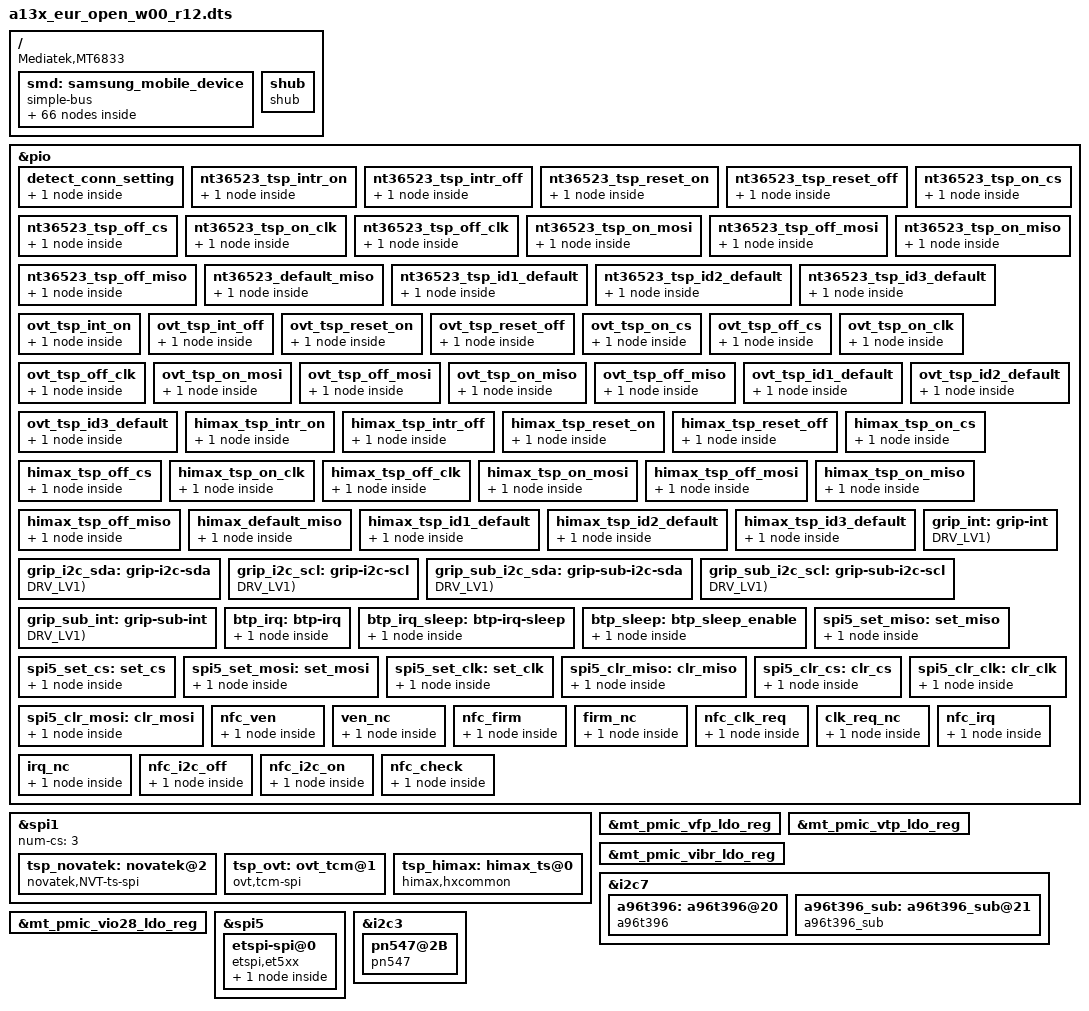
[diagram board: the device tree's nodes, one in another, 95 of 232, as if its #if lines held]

/*
 * Copyright (c) 2018 Samsung Electronics Co., Ltd.
 *              http://www.samsung.com
 *
 * This program is free software; you can redistribute it and/or modify
 * it under the terms of the GNU General Public License version 2 as
 * published by the Free Software Foundation.
*/

/dts-v1/;
/plugin/;
/ {
	fragment@smd {
		target-path = "/";
		__overlay__ {
			smd: samsung_mobile_device {
				compatible = "simple-bus";
			};
		};
	};
};

/* #include "../mtk_charger.dtsi" */                 /* From mtk_charger.py */

&smd {
	mtk_charger: mtk-charger {
		compatible = "samsung,mtk-charger";
		charger,vbus_min_charger_voltage = <4500000>;
		charger,vbus_normal_mivr_voltage = <4500000>;
		charger,gpio_ilim = <&pio 140 0x0>;
		charger,gpio_chgenb = <&pio 135 0x0>;
		charger,max_icl = <3250>;
		charger,ib_fcc = <100>;
	};
};

/* #include "../mtk_fuelgauge.dtsi" */               /* From mtk_fuelgauge.py */
&smd {
	battery {
		battery,fuelgauge_name = "mtk-fg-battery";
	};

	/* battery_prop.dtsi */
	bat_gm30: mtk_battery{
		compatible = "mediatek,bat_gm30";
		DIFFERENCE_FULLOCV_ITH = <(300)>;
	/*	Charging termination current*/
		SHUTDOWN_1_TIME = <(60)>;
	/*	If ui_soc shows 1% more than X minites, system will shutdown*/
		KEEP_100_PERCENT = <(1)>;
	/* 	The ui_soc will keep 100% until SOC drop X percents after unplugged */
		R_FG_VALUE = <(5)>;
	/*	R_sense resistance*/
		EMBEDDED_SEL = <(0)>;
	/*	Configures whether using embedded battery or not*/
		PMIC_SHUTDOWN_CURRENT = <(20)>;
	/*	System shutdown current*/
		FG_METER_RESISTANCE = <(100)>;
	/*	The resistance of PCB*/
		CAR_TUNE_VALUE = <(99)>;
	/*	Tune value for current measurement*/
		PMIC_MIN_VOL = <(33500)>;
	/*	vboot voltage for gauge 0%*/
		POWERON_SYSTEM_IBOOT = <(500)>;
	/*	power on system iboot*/
		SHUTDOWN_GAUGE0 = <(0)>;
	/*	Shutdown condition2 switch*/
		SHUTDOWN_GAUGE0_VOLTAGE = <(34000)>;
	/*	shutdown gauge 0% voltage*/
		TEMPERATURE_T0 = <(50)>;
	/*	Battery temperature T0*/
		TEMPERATURE_T1 = <(25)>;
	/*	Battery temperature T1*/
		TEMPERATURE_T2 = <(10)>;
	/*	Battery temperature T2*/
		TEMPERATURE_T3 = <(0)>;
	/*	Battery temperature T3*/
		TEMPERATURE_T4 = <(-10)>;
	/*	Battery temperature T4*/
		TEMPERATURE_T5 = <(-20)>;
	/*	Battery temperature T5*/
		g_FG_PSEUDO100_T0 = <(93)>;
	/*	Pseudo 100% percentage at T0*/
		g_FG_PSEUDO100_T1 = <(93)>;
	/*	Pseudo 100% percentage at T1*/
		g_FG_PSEUDO100_T2 = <(93)>;
	/*	Pseudo 100% percentage at T2*/
		g_FG_PSEUDO100_T3 = <(93)>;
	/*	Pseudo 100% percentage at T3*/
		g_FG_PSEUDO100_T4 = <(93)>;
	/*	Pseudo 100% percentage at T4*/
		g_FG_PSEUDO100_T5 = <(93)>;
	/*	Pseudo 100% percentage at T4*/
		Q_MAX_SYS_VOLTAGE_BAT0 = <(3350)>;
	/*	Pseudo1 for hide percentage*/
		Q_MAX_SYS_VOLTAGE_BAT1 = <(3350)>;
	/*	Pseudo1 for hide percentage*/
		Q_MAX_SYS_VOLTAGE_BAT2 = <(3350)>;
	/*	Pseudo1 for hide percentage*/
		Q_MAX_SYS_VOLTAGE_BAT3 = <(3350)>;
	/*	Pseudo1 for hide percentage*/
		COM_FG_METER_RESISTANCE = <(100)>;
	/*	compensate The resistance of PCB*/
		COM_R_FG_VALUE = <(0)>;
	/*	compensate R_sense resistance*/
		enable_tmp_intr_suspend = <(0)>;
	/* Enable update temp when suspend */
		ACTIVE_TABLE = <(6)>;
	/* Table numbers per battery*/
		MULTI_TEMP_GAUGE0 = <(1)>;
	/* Multi gauge0 enable*/
		HWOCV_OLDOCV_DIFF = <(100)>;
	/* Diff of HWOCV and SWOCV*/
	UI_FULL_LIMIT_EN = <(1)>;
	UI_FULL_LIMIT_SOC0 = <(9500)>;
	UI_FULL_LIMIT_ITH0 = <(8500)>;
	UI_FULL_LIMIT_SOC1 = <(9600)>;
	UI_FULL_LIMIT_ITH1 = <(7500)>;
	UI_FULL_LIMIT_SOC2 = <(9700)>;
	UI_FULL_LIMIT_ITH2 = <(6600)>;
	UI_FULL_LIMIT_SOC3 = <(9800)>;
	UI_FULL_LIMIT_ITH3 = <(6000)>;
	UI_FULL_LIMIT_SOC4 = <(9900)>;
	UI_FULL_LIMIT_ITH4 = <(5000)>;
/* Using current to limit uisoc in 100% case*/
	/* battery_table.dtsi*/
	battery0_profile_t0_num = <100>;
	battery0_profile_t0_col = <3>;
	battery0_profile_t0 =
	<
	0       43520   850
	486     43380   866
	972     43251   875
	1458    43130   897
	1944    43004   875
	2430    42881   875
	2916    42760   875
	3402    42644   875
	3888    42530   900
	4375    42407   875
	4861    42293   881
	5347    42178   900
	5833    42054   875
	6319    41941   897
	6805    41820   875
	7291    41714   875
	7777    41601   900
	8263    41485   875
	8749    41372   875
	9235    41267   897
	9721    41155   875
	10207   41051   875
	10693   40945   875
	11179   40837   884
	11665   40739   875
	12152   40642   900
	12638   40542   894
	13124   40446   919
	13610   40350   900
	14096   40253   900
	14582   40162   919
	15068   40070   925
	15554   39979   925
	16040   39898   941
	16526   39817   950
	17012   39736   950
	17498   39655   962
	17984   39573   975
	18470   39492   975
	18956   39411   1000
	19442   39329   1025
	19928   39210   975
	20415   39078   938
	20901   38949   878
	21387   38849   875
	21873   38773   850
	22359   38699   850
	22845   38635   850
	23331   38580   850
	23817   38521   850
	24303   38472   850
	24789   38423   850
	25275   38374   875
	25761   38326   850
	26247   38285   869
	26733   38239   850
	27219   38200   875
	27705   38157   866
	28192   38115   868
	28678   38082   872
	29164   38050   875
	29650   38007   853
	30136   37975   875
	30622   37952   900
	31108   37919   900
	31594   37887   900
	32080   37865   907
	32566   37841   925
	33052   37810   925
	33538   37765   900
	34024   37684   861
	34510   37614   865
	34996   37550   851
	35482   37511   859
	35968   37465   857
	36455   37424   853
	36941   37374   850
	37427   37337   875
	37913   37304   875
	38399   37272   875
	38885   37230   875
	39371   37185   900
	39857   37120   875
	40343   37063   875
	40829   37004   888
	41315   36942   879
	41801   36861   881
	42287   36806   860
	42773   36790   875
	43259   36780   891
	43745   36767   907
	44232   36751   948
	44718   36719   976
	45204   36643   1018
	45690   36372   937
	46176   35944   969
	46662   35387   1000
	47148   34581   1041
	47634   33318   1181
	48120   30130   10325
	>;
	battery0_profile_t1_num = <100>;
	battery0_profile_t1_col = <3>;
	battery0_profile_t1 =
	<
	0       43320   1450
	486     43164   1450
	972     43033   1475
	1458    42911   1475
	1944    42789   1475
	2430    42671   1475
	2916    42550   1456
	3402    42434   1475
	3888    42320   1475
	4375    42197   1440
	4861    42083   1431
	5347    41968   1428
	5833    41854   1437
	6319    41741   1428
	6805    41628   1431
	7291    41514   1425
	7777    41401   1425
	8263    41295   1425
	8749    41184   1407
	9235    41078   1403
	9721    40975   1412
	10207   40871   1425
	10693   40765   1425
	11179   40667   1416
	11665   40569   1425
	12152   40475   1450
	12638   40382   1450
	13124   40277   1450
	13610   40190   1450
	14096   40093   1447
	14582   40002   1444
	15068   39920   1460
	15554   39839   1450
	16040   39758   1450
	16526   39687   1500
	17012   39606   1500
	17498   39525   1500
	17984   39443   1504
	18470   39354   1525
	18956   39243   1490
	19442   39109   1425
	19928   38980   1344
	20415   38875   1319
	20901   38787   1300
	21387   38719   1313
	21873   38654   1300
	22359   38589   1300
	22845   38535   1290
	23331   38480   1300
	23817   38431   1291
	24303   38384   1300
	24789   38343   1300
	25275   38294   1300
	25761   38257   1303
	26247   38217   1325
	26733   38182   1309
	27219   38140   1325
	27705   38107   1341
	28192   38075   1332
	28678   38042   1350
	29164   38010   1350
	29650   37987   1375
	30136   37955   1375
	30622   37926   1375
	31108   37900   1376
	31594   37877   1384
	32080   37855   1400
	32566   37822   1378
	33052   37790   1375
	33538   37747   1375
	34024   37707   1356
	34510   37672   1360
	34996   37630   1351
	35482   37591   1359
	35968   37552   1350
	36455   37512   1372
	36941   37480   1375
	37427   37447   1375
	37913   37414   1394
	38399   37368   1385
	38885   37310   1376
	39371   37248   1393
	39857   37192   1400
	40343   37134   1423
	40829   37063   1412
	41315   36975   1425
	41801   36935   1425
	42287   36920   1460
	42773   36910   1475
	43259   36894   1500
	43745   36867   1514
	44232   36833   1573
	44718   36727   1613
	45204   36421   1607
	45690   35937   1688
	46176   35299   1804
	46662   34415   1951
	47148   32710   2488
	47634   30570   11550
	48120   30570   11550
	>;
	battery0_profile_t2_num = <100>;
	battery0_profile_t2_col = <3>;
	battery0_profile_t2 =
	<
	0       43000   3200
	486     42808   3293
	972     42661   3412
	1458    42531   3472
	1944    42404   3476
	2430    42281   3478
	2916    42160   3481
	3402    42044   3484
	3888    41930   3475
	4375    41817   3485
	4861    41695   3456
	5347    41579   3431
	5833    41474   3450
	6319    41361   3425
	6805    41255   3425
	7291    41144   3425
	7777    41041   3425
	8263    40931   3416
	8749    40834   3407
	9235    40737   3425
	9721    40640   3425
	10207   40541   3444
	10693   40435   3419
	11179   40337   3425
	11665   40229   3375
	12152   40138   3391
	12638   40047   3381
	13124   39957   3378
	13610   39875   3400
	14096   39794   3375
	14582   39712   3375
	15068   39640   3415
	15554   39559   3425
	16040   39472   3409
	16526   39382   3425
	17012   39269   3381
	17498   39146   3350
	17984   39008   3268
	18470   38894   3225
	18956   38801   3200
	19442   38720   3200
	19928   38655   3200
	20415   38590   3200
	20901   38534   3222
	21387   38479   3225
	21873   38426   3250
	22359   38377   3250
	22845   38329   3275
	23331   38280   3275
	23817   38241   3300
	24303   38202   3325
	24789   38162   3347
	25275   38130   3363
	25761   38087   3378
	26247   38055   3400
	26733   38022   3425
	27219   37990   3425
	27705   37967   3466
	28192   37935   3500
	28678   37911   3500
	29164   37885   3525
	29650   37859   3528
	30136   37842   3569
	30622   37822   3600
	31108   37800   3601
	31594   37784   3641
	32080   37757   3657
	32566   37732   3697
	33052   37700   3700
	33538   37667   3728
	34024   37627   3750
	34510   37592   3795
	34996   37559   3850
	35482   37517   3866
	35968   37482   3932
	36455   37434   3972
	36941   37374   4026
	37427   37314   4104
	37913   37249   4144
	38399   37190   4235
	38885   37119   4325
	39371   37028   4398
	39857   36965   4501
	40343   36932   4666
	40829   36905   4816
	41315   36877   5048
	41801   36845   5310
	42287   36790   5653
	42773   36689   6028
	43259   36466   6433
	43745   36033   6914
	44232   35419   7720
	44718   34544   8974
	45204   33115   11297
	45690   30950   12525
	46176   30950   12525
	46662   30950   12525
	47148   30950   12525
	47634   30950   12525
	48120   30950   12525
	>;
	battery0_profile_t3_num = <100>;
	battery0_profile_t3_col = <3>;
	battery0_profile_t3 =
	<
	0       42520   5950
	486     42262   6183
	972     42098   6518
	1458    41961   6640
	1944    41824   6714
	2430    41701   6753
	2916    41580   6775
	3402    41464   6816
	3888    41350   6825
	4375    41237   6840
	4861    41123   6825
	5347    41017   6847
	5833    40909   6825
	6319    40812   6847
	6805    40715   6844
	7291    40604   6825
	7777    40501   6825
	8263    40385   6784
	8749    40274   6782
	9235    40177   6800
	9721    40080   6800
	10207   39984   6778
	10693   39903   6781
	11179   39821   6784
	11665   39739   6800
	12152   39658   6791
	12638   39587   6825
	13124   39497   6803
	13610   39410   6813
	14096   39312   6797
	14582   39196   6756
	15068   39069   6680
	15554   38949   6625
	16040   38836   6584
	16526   38747   6569
	17012   38666   6550
	17498   38600   6575
	17984   38536   6579
	18470   38479   6600
	18956   38418   6635
	19442   38370   6675
	19928   38321   6691
	20415   38275   6706
	20901   38234   6725
	21387   38194   6750
	21873   38156   6775
	22359   38115   6794
	22845   38082   6835
	23331   38050   6850
	23817   38018   6891
	24303   37984   6907
	24789   37952   6925
	25275   37930   6975
	25761   37909   7003
	26247   37892   7044
	26733   37876   7084
	27219   37860   7125
	27705   37843   7183
	28192   37827   7214
	28678   37811   7295
	29164   37795   7351
	29650   37777   7407
	30136   37752   7488
	30622   37722   7544
	31108   37689   7626
	31594   37657   7723
	32080   37622   7813
	32566   37582   7939
	33052   37540   8076
	33538   37495   8238
	34024   37437   8422
	34510   37374   8610
	34996   37309   8853
	35482   37238   9080
	35968   37170   9352
	36455   37096   9676
	36941   37004   10017
	37427   36935   10393
	37913   36894   10858
	38399   36862   11389
	38885   36830   11982
	39371   36791   12670
	39857   36740   13453
	40343   36656   14301
	40829   36424   15025
	41315   35986   15823
	41801   35349   16953
	42287   34442   18475
	42773   33430   18575
	43259   33430   18575
	43745   33430   18575
	44232   33430   18575
	44718   33430   18575
	45204   33430   18575
	45690   33430   18575
	46176   33430   18575
	46662   33430   18575
	47148   33430   18575
	47634   33430   18575
	48120   33430   18575
	>;
	battery0_profile_t4_num = <100>;
	battery0_profile_t4_col = <3>;
	battery0_profile_t4 =
	<
	0       42010   11330
	486     41738   11604
	972     41429   12066
	1458    41171   12469
	1944    40989   12751
	2430    40838   12878
	2916    40700   12919
	3402    40570   12916
	3888    40440   12875
	4375    40311   12819
	4861    40181   12744
	5347    40058   12703
	5833    39949   12675
	6319    39842   12650
	6805    39745   12650
	7291    39648   12616
	7777    39541   12526
	8263    39441   12509
	8749    39332   12437
	9235    39227   12378
	9721    39115   12312
	10207   39013   12272
	10693   38923   12250
	11179   38841   12216
	11665   38759   12200
	12152   38694   12184
	12638   38622   12175
	13124   38565   12175
	13610   38510   12200
	14096   38456   12178
	14582   38407   12200
	15068   38358   12210
	15554   38310   12225
	16040   38261   12241
	16526   38215   12256
	17012   38174   12297
	17498   38140   12325
	17984   38097   12329
	18470   38065   12350
	18956   38032   12375
	19442   38010   12450
	19928   37977   12475
	20415   37955   12506
	20901   37931   12568
	21387   37905   12626
	21873   37874   12675
	22359   37855   12770
	22845   37832   12819
	23331   37800   12900
	23817   37778   13031
	24303   37744   13121
	24789   37712   13242
	25275   37670   13327
	25761   37626   13460
	26247   37577   13639
	26733   37535   13728
	27219   37480   13875
	27705   37420   14031
	28192   37359   14202
	28678   37294   14386
	29164   37230   14552
	29650   37155   14720
	30136   37090   14944
	30622   37028   15148
	31108   36979   15354
	31594   36947   15613
	32080   36905   15847
	32566   36863   16130
	33052   36790   16376
	33538   36673   16644
	34024   36429   16891
	34510   36018   17215
	34996   35399   17761
	35482   34431   18699
	35968   32802   17069
	36455   31080   12750
	36941   31080   12750
	37427   31080   12750
	37913   31080   12750
	38399   31080   12750
	38885   31080   12750
	39371   31080   12750
	39857   31080   12750
	40343   31080   12750
	40829   31080   12750
	41315   31080   12750
	41801   31080   12750
	42287   31080   12750
	42773   31080   12750
	43259   31080   12750
	43745   31080   12750
	44232   31080   12750
	44718   31080   12750
	45204   31080   12750
	45690   31080   12750
	46176   31080   12750
	46662   31080   12750
	47148   31080   12750
	47634   31080   12750
	48120   31080   12750
	>;
	battery0_profile_t5_num = <100>;
	battery0_profile_t5_col = <3>;
	battery0_profile_t5 =
	<
	0       40920   10780
	483     40610   11233
	967     40337   12231
	1450    40095   12975
	1933    39872   13686
	2417    39674   14479
	2900    39510   15208
	3383    39378   15667
	3867    39258   15931
	4350    39150   16075
	4833    39042   16178
	5317    38929   16164
	5800    38830   16208
	6283    38733   16319
	6767    38652   16378
	7250    38573   16404
	7733    38509   16464
	8217    38444   16519
	8700    38390   16625
	9183    38335   16666
	9667    38292   16706
	10150   38244   16725
	10633   38200   16750
	11117   38158   16752
	11600   38126   16810
	12083   38087   16833
	12567   38052   16965
	13050   38019   16990
	13533   37987   17100
	14017   37955   17176
	14500   37919   17218
	14983   37880   17323
	15467   37838   17390
	15950   37794   17510
	16433   37738   17550
	16917   37683   17714
	17400   37629   17828
	17883   37564   17981
	18367   37500   18070
	18850   37427   18222
	19333   37361   18385
	19817   37286   18407
	20300   37222   18563
	20783   37158   18764
	21267   37093   18919
	21750   37039   19080
	22233   36974   19247
	22717   36910   19451
	23200   36824   19655
	23683   36692   19921
	24167   36470   20134
	24650   36118   20420
	25133   35546   20803
	25617   34662   21167
	26100   33270   18200
	26583   32530   16450
	27067   32530   16450
	27550   32530   16450
	28033   32530   16450
	28517   32530   16450
	29000   32530   16450
	29483   32530   16450
	29967   32530   16450
	30450   32530   16450
	30933   32530   16450
	31417   32530   16450
	31900   32530   16450
	32383   32530   16450
	32867   32530   16450
	33350   32530   16450
	33833   32530   16450
	34317   32530   16450
	34800   32530   16450
	35283   32530   16450
	35767   32530   16450
	36250   32530   16450
	36733   32530   16450
	37217   32530   16450
	37700   32530   16450
	38183   32530   16450
	38667   32530   16450
	39150   32530   16450
	39633   32530   16450
	40117   32530   16450
	40600   32530   16450
	41083   32530   16450
	41567   32530   16450
	42050   32530   16450
	42533   32530   16450
	43017   32530   16450
	43500   32530   16450
	43983   32530   16450
	44467   32530   16450
	44950   32530   16450
	45433   32530   16450
	45917   32530   16450
	46400   32530   16450
	46883   32530   16450
	47367   32530   16450
	47850   32530   16450
	>;

	/* battery_prop_dim2_ext.dtsi */
	/*vboot voltage for gauge 0%*/
	g_PMIC_MIN_VOL_row = <4>;
	g_PMIC_MIN_VOL_col = <10>;
	g_PMIC_MIN_VOL =
	<
		32700  32700  32700  32700
		32700  32700  32700  32700
		32700  32700  32700  32700
		32200  32200  32200  32200
		31000  31000  31000  31000
		31500  31500  31500  31500
		31000  31000  31000  31000
		31000  31000  31000  31000
		31000  31000  31000  31000
		31000  31000  31000  31200
	>;
	/*boot_up current for gauge 0%*/
	g_PON_SYS_IBOOT_row = <4>;
	g_PON_SYS_IBOOT_col = <10>;
	g_PON_SYS_IBOOT =
	<
		5000  5000  5000  5000
		5000  5000  5000  5000
		5000  5000  5000  5000
		5000  5000  5000  5000
		5000  5000  5000  5000
		5000  5000  5000  5000
		5000  5000  5000  5000
		5000  5000  5000  5000
		5000  5000  5000  5000
		5000  5000  5000  5000
	>;
	/*Pseudo1 hide percentage*/
	g_QMAX_SYS_VOL_row = <4>;
	g_QMAX_SYS_VOL_col = <10>;
	g_QMAX_SYS_VOL =
	<
		33600  33600  33600  33600
		33600  33600  33600  33600
		33600  33600  33600  33600
		33600  33600  33600  33600
		33600  33600  33600  33600
		32500  32500  32500  32500
		32800  32800  32800  32800
		32800  32800  32800  32800
		32800  32800  32800  32800
		32800  32800  32800  32800
	>;
	/*Pseudo100 percentage setting*/
	g_FG_PSEUDO100_row = <4>;
	g_FG_PSEUDO100_col = <10>;
	g_FG_PSEUDO100 =
	<
		91  100  100  100
		91  100  100  100
		91  100  100  100
		91  100  100  100
		91  100  100  100
		91  100  100  100
		100  100  100  100
		100  100  100  100
		100  100  100  100
		100  100  100  100
	>;

	};
};

/* /home/dpi/qb5_8814/workspace/P4_1716/android/kernel/kmodule/battery/fuelgauge/mtk_fuelgauge/mtk_fuelgauge.a13x.dtsi */
&smd {
	battery {
		battery,fuelgauge_name = "mtk-fg-battery";
	};

	/* battery_prop.dtsi */
bat_gm30: mtk_battery{
	compatible = "mediatek,bat_gm30";

	RBAT_TYPE = <(100)>;
	RBAT_PULL_UP_R = <(100000)>;

	rbat_temperature_table_num = <21>;
	rbat_battery_temperature =
	<
		(-40) 4397119
		(-35) 3088598
		(-30) 2197225
		(-25) 1581880
		(-20) 1151036
		(-15) 846578
		(-10) 628988
		(-5) 471632
		0 357011
		5 272499
		10 209709
		15 162650
		20 127080
		25 100000
		30 79221
		35 63167
		40 50676
		45 40903
		50 33194
		55 27090
		60 22224 >;
/* battery temperature table type - NTC table */
	BatteryID_GPIO = <&pio 184 0>;
/* Battery ID distinction */
	DIFFERENCE_FULLOCV_ITH = <(300)>; /* a13x-5g : 300mA */
/*	Charging termination current*/
	SHUTDOWN_1_TIME = <(60)>;
/*	If ui_soc shows 1% more than X minites, system will shutdown*/
	KEEP_100_PERCENT = <(1)>;
/*	The ui_soc will keep 100% until SOC drop X percents after unplugged*/
	R_FG_VALUE = <(5)>;
/*	R_sense resistance*/
	EMBEDDED_SEL = <(0)>;
/*	Configures whether using embedded battery or not*/
	PMIC_SHUTDOWN_CURRENT = <(20)>;
/*	System shutdown current*/
	FG_METER_RESISTANCE = <(100)>;
/*	The resistance of PCB*/
	CAR_TUNE_VALUE = <(102)>;
/*	Tune value for current measurement*/
	PMIC_MIN_VOL = <(33500)>;
/*	vboot voltage for gauge 0%*/
	POWERON_SYSTEM_IBOOT = <(500)>;
/*	power on system iboot*/
	SHUTDOWN_GAUGE0 = <(0)>;
/*	Shutdown condition2 switch*/
	SHUTDOWN_GAUGE0_VOLTAGE = <(34000)>;
/*	shutdown gauge 0% voltage*/
	TEMPERATURE_T0 = <(50)>;
/*	Battery temperature T0*/
	TEMPERATURE_T1 = <(25)>;
/*	Battery temperature T1*/
	TEMPERATURE_T2 = <(10)>;
/*	Battery temperature T2*/
	TEMPERATURE_T3 = <(0)>;
/*	Battery temperature T3*/
	TEMPERATURE_T4 = <(-10)>;
/*	Battery temperature T4*/
	TEMPERATURE_T5 = <(-20)>;
/*	Battery temperature T5*/
	g_FG_PSEUDO100_T0 = <(100)>;
/*	Pseudo 100% percentage at T0*/
	g_FG_PSEUDO100_T1 = <(100)>;
/*	Pseudo 100% percentage at T1*/
	g_FG_PSEUDO100_T2 = <(100)>;
/*	Pseudo 100% percentage at T2*/
	g_FG_PSEUDO100_T3 = <(100)>;
/*	Pseudo 100% percentage at T3*/
	g_FG_PSEUDO100_T4 = <(100)>;
/*	Pseudo 100% percentage at T4*/
	g_FG_PSEUDO100_T5 = <(100)>;
/*	Pseudo 100% percentage at T4*/
	Q_MAX_SYS_VOLTAGE_BAT0 = <(3350)>;
/*	Pseudo1 for hide percentage*/
	Q_MAX_SYS_VOLTAGE_BAT1 = <(3350)>;
/*	Pseudo1 for hide percentage*/
	Q_MAX_SYS_VOLTAGE_BAT2 = <(3350)>;
/*	Pseudo1 for hide percentage*/
	Q_MAX_SYS_VOLTAGE_BAT3 = <(3350)>;
/*	Pseudo1 for hide percentage*/
	COM_FG_METER_RESISTANCE = <(100)>;
/*	compensate The resistance of PCB*/
	COM_R_FG_VALUE = <(0)>;
/*	compensate R_sense resistance*/
	enable_tmp_intr_suspend = <(0)>;
/* Enable update temp when suspend */
	ACTIVE_TABLE = <(6)>;
/* Table numbers per battery*/
	MULTI_TEMP_GAUGE0 = <(1)>;
/* Multi gauge0 enable*/
	HWOCV_OLDOCV_DIFF = <(100)>;
/* Diff of HWOCV and SWOCV*/
	UI_FULL_LIMIT_EN = <(1)>;
	UI_FULL_LIMIT_SOC0 = <(9545)>;
	UI_FULL_LIMIT_ITH0 = <(11000)>;
	UI_FULL_LIMIT_SOC1 = <(9645)>;
	UI_FULL_LIMIT_ITH1 = <(8500)>;
	UI_FULL_LIMIT_SOC2 = <(9745)>;
	UI_FULL_LIMIT_ITH2 = <(7300)>;
	UI_FULL_LIMIT_SOC3 = <(9845)>;
	UI_FULL_LIMIT_ITH3 = <(5700)>;
	UI_FULL_LIMIT_SOC4 = <(9945)>;
	UI_FULL_LIMIT_ITH4 = <(4300)>;
/* Using current to limit uisoc in 100% case*/
/* battery_table.dtsi*/
battery0_profile_t0_num = <100>;
battery0_profile_t0_col = <3>;
battery0_profile_t0 =
<
0       43220   900
480     43076   900
961     42934   900
1441    42806   900
1921    42689   911
2402    42567   901
2882    42455   925
3362    42333   900
3842    42221   900
4323    42113   911
4803    41997   901
5283    41893   925
5764    41780   918
6244    41677   922
6724    41566   925
7205    41464   925
7685    41352   925
8165    41248   925
8645    41145   948
9126    41039   925
9606    40943   950
10086   40840   932
10567   40741   950
11047   40645   950
11527   40552   964
12008   40484   1004
12488   40397   1006
12968   40261   959
13448   40133   975
13929   40037   989
14409   39985   1000
14889   39920   980
15370   39844   985
15850   39760   975
16330   39690   1000
16811   39612   1005
17291   39540   1025
17771   39463   1025
18252   39388   1051
18732   39318   1075
19212   39238   1075
19692   39150   1075
20173   39020   1003
20653   38877   950
21133   38780   950
21614   38696   925
22094   38625   925
22574   38566   925
23055   38508   925
23535   38460   925
24015   38411   925
24495   38353   925
24976   38314   925
25456   38268   925
25936   38228   943
26417   38184   933
26897   38152   950
27377   38109   939
27858   38077   950
28338   38037   931
28818   38003   934
29298   37971   950
29779   37949   975
30259   37917   975
30739   37884   955
31220   37862   975
31700   37840   1000
32180   37814   990
32661   37786   995
33141   37762   995
33621   37710   955
34102   37638   949
34582   37554   909
35062   37505   931
35542   37473   950
36023   37427   939
36503   37389   949
36983   37347   942
37464   37307   932
37944   37274   928
38424   37250   950
38905   37208   927
39385   37163   950
39865   37109   950
40345   37043   950
40826   36989   950
41306   36934   972
41786   36847   932
42267   36797   933
42747   36781   950
43227   36770   938
43708   36760   978
44188   36745   1000
44668   36719   1025
45148   36652   1049
45629   36402   1014
46109   35989   1025
46589   35455   1063
47070   34691   1084
47550   33540   1150
>;
battery0_profile_t1_num = <100>;
battery0_profile_t1_col = <3>;
battery0_profile_t1 =
<
0       43120   1150
480     42966   1150
961     42834   1175
1441    42714   1195
1921    42599   1189
2402    42487   1200
2882    42375   1200
3362    42263   1200
3842    42151   1200
4323    42043   1186
4803    41937   1176
5283    41829   1200
5764    41723   1207
6244    41618   1203
6724    41516   1225
7205    41405   1227
7685    41302   1233
8165    41198   1242
8645    41086   1225
9126    40989   1250
9606    40884   1231
10086   40804   1275
10567   40750   1333
11047   40712   1373
11527   40637   1361
12008   40501   1321
12488   40301   1281
12968   40114   1259
13448   39973   1275
13929   39866   1250
14409   39783   1250
14889   39726   1290
15370   39682   1310
15850   39660   1350
16330   39632   1360
16811   39572   1330
17291   39500   1330
17771   39433   1360
18252   39358   1375
18732   39288   1375
19212   39196   1350
19692   39091   1329
20173   38960   1267
20653   38837   1200
21133   38740   1167
21614   38666   1168
22094   38595   1150
22574   38541   1163
23055   38488   1152
23535   38433   1141
24015   38388   1168
24495   38342   1173
24976   38294   1162
25456   38256   1172
25936   38216   1168
26417   38174   1150
26897   38142   1173
27377   38109   1175
27858   38077   1175
28338   38045   1175
28818   38013   1175
29298   37981   1175
29779   37959   1200
30259   37928   1200
30739   37904   1200
31220   37876   1185
31700   37860   1225
32180   37834   1200
32661   37808   1200
33141   37784   1180
33621   37762   1200
34102   37719   1174
34582   37677   1150
35062   37645   1150
35542   37613   1150
36023   37581   1161
36503   37539   1150
36983   37507   1167
37464   37474   1150
37944   37442   1150
38424   37410   1162
38905   37368   1177
39385   37323   1183
39865   37259   1175
40345   37203   1198
40826   37149   1200
41306   37084   1200
41786   36997   1182
42267   36944   1200
42747   36921   1200
43227   36915   1212
43708   36898   1225
44188   36882   1244
44668   36859   1275
45148   36802   1299
45629   36582   1300
46109   36159   1308
46589   35617   1407
47070   34853   1470
47550   33730   1600
>;
battery0_profile_t2_num = <100>;
battery0_profile_t2_col = <3>;
battery0_profile_t2 =
<
0       42790   2375
480     42616   2420
961     42484   2500
1441    42364   2540
1921    42239   2536
2402    42128   2551
2882    42025   2575
3362    41916   2581
3842    41811   2600
4323    41709   2625
4803    41607   2650
5283    41493   2650
5764    41383   2632
6244    41278   2672
6724    41176   2675
7205    41075   2675
7685    40979   2658
8165    40899   2714
8645    40843   2838
9126    40795   2912
9606    40733   2925
10086   40622   2907
10567   40435   2776
11047   40211   2656
11527   40033   2600
12008   39902   2575
12488   39806   2575
12968   39727   2575
13448   39663   2598
13929   39614   2638
14409   39567   2653
14889   39535   2693
15370   39500   2700
15850   39451   2700
16330   39387   2700
16811   39310   2696
17291   39214   2656
17771   39110   2597
18252   38982   2526
18732   38860   2436
19212   38761   2400
19692   38681   2381
20173   38619   2384
20653   38561   2400
21133   38502   2375
21614   38452   2375
22094   38396   2375
22574   38358   2390
23055   38310   2375
23535   38262   2375
24015   38223   2400
24495   38184   2420
24976   38147   2400
25456   38110   2425
25936   38077   2425
26417   38045   2425
26897   38013   2425
27377   37981   2425
27858   37959   2425
28338   37933   2441
28818   37905   2443
29298   37881   2447
29779   37860   2475
30259   37839   2475
30739   37823   2492
31220   37807   2507
31700   37791   2548
32180   37775   2563
32661   37758   2625
33141   37733   2660
33621   37704   2708
34102   37672   2748
34582   37635   2813
35062   37597   2857
35542   37565   2937
36023   37530   3000
36503   37491   3071
36983   37448   3125
37464   37394   3182
37944   37337   3264
38424   37279   3344
38905   37221   3400
39385   37157   3504
39865   37081   3584
40345   37009   3645
40826   36976   3764
41306   36960   3899
41786   36938   4044
42267   36918   4204
42747   36894   4428
43227   36825   4653
43708   36675   4826
44188   36321   4897
44668   35789   5243
45148   35066   5744
45629   33910   6383
46109   33410   6625
46589   33410   6625
47070   33410   6625
47550   33410   6625
>;
battery0_profile_t3_num = <100>;
battery0_profile_t3_col = <3>;
battery0_profile_t3 =
<
0       42290   4675
480     42070   4795
961     41924   4990
1441    41796   5090
1921    41672   5135
2402    41550   5175
2882    41438   5230
3362    41323   5250
3842    41212   5270
4323    41101   5275
4803    41009   5326
5283    40934   5423
5764    40870   5531
6244    40806   5571
6724    40723   5589
7205    40595   5496
7685    40412   5376
8165    40200   5212
8645    40025   5132
9126    39888   5100
9606    39787   5124
10086   39697   5100
10567   39632   5138
11047   39574   5175
11527   39515   5187
12008   39467   5225
12488   39419   5242
12968   39361   5232
13448   39304   5250
13929   39235   5238
14409   39143   5200
14889   39049   5163
15370   38937   5092
15850   38825   5028
16330   38723   4975
16811   38643   4972
17291   38571   4950
17771   38505   4950
18252   38451   4974
18732   38393   4964
19212   38345   4975
19692   38297   4975
20173   38259   5009
20653   38211   5025
21133   38168   5025
21614   38136   5055
22094   38096   5075
22574   38062   5100
23055   38030   5100
23535   37992   5125
24015   37966   5155
24495   37934   5175
24976   37915   5211
25456   37899   5278
25936   37883   5358
26417   37870   5451
26897   37861   5589
27377   37845   5732
27858   37839   5905
28338   37823   6044
28818   37807   6229
29298   37791   6412
29779   37770   6587
30259   37748   6785
30739   37723   6962
31220   37693   7133
31700   37671   7317
32180   37629   7453
32661   37596   7610
33141   37555   7749
33621   37520   7909
34102   37472   8045
34582   37423   8181
35062   37365   8317
35542   37309   8477
36023   37245   8638
36503   37181   8773
36983   37117   8972
37464   37055   9172
37944   37014   9416
38424   36982   9652
38905   36960   9928
39385   36928   10208
39865   36891   10549
40345   36811   10868
40826   36666   11188
41306   36398   11438
41786   35984   11904
42267   35377   12660
42747   34472   13682
43227   33460   14675
43708   33460   14675
44188   33460   14675
44668   33460   14675
45148   33460   14675
45629   33460   14675
46109   33460   14675
46589   33460   14675
47070   33460   14675
47550   33460   14675
>;
battery0_profile_t4_num = <100>;
battery0_profile_t4_col = <3>;
battery0_profile_t4 =
<
0       41850   9125
480     41360   9576
961     41068   10431
1441    40916   10770
1921    40789   10861
2402    40667   10848
2882    40510   10736
3362    40319   10564
3842    40111   10387
4323    39940   10364
4803    39797   10294
5283    39693   10209
5764    39606   10275
6244    39535   10341
6724    39456   10300
7205    39376   10352
7685    39303   10341
8165    39227   10360
8645    39154   10344
9126    39074   10325
9606    38994   10297
10086   38907   10275
10567   38811   10192
11047   38715   10152
11527   38627   10122
12008   38544   10075
12488   38472   10056
12968   38416   10066
13448   38352   10026
13929   38303   10092
14409   38255   10129
14889   38206   10150
15370   38162   9995
15850   38130   10100
16330   38088   10225
16811   38056   10135
17291   38024   10235
17771   38006   10342
18252   37990   10510
18732   37980   10846
19212   37968   11030
19692   37952   11209
20173   37936   11405
20653   37920   11629
21133   37903   11842
21614   37894   12092
22094   37880   12354
22574   37855   12621
23055   37839   12891
23535   37823   13194
24015   37807   13444
24495   37791   13757
24976   37765   13978
25456   37739   14141
25936   37716   14165
26417   37694   14399
26897   37662   14542
27377   37629   14689
27858   37597   14761
28338   37565   15045
28818   37529   15134
29298   37481   15174
29779   37433   15239
30259   37385   15333
30739   37328   15395
31220   37274   15510
31700   37220   15575
32180   37156   15645
32661   37104   15760
33141   37056   15920
33621   37022   16101
34102   36989   16305
34582   36951   16489
35062   36910   16693
35542   36838   16855
36023   36711   17044
36503   36460   17180
36983   36017   17450
37464   35365   18050
37944   34392   18881
38424   33520   18825
38905   33520   18825
39385   33520   18825
39865   33520   18825
40345   33520   18825
40826   33520   18825
41306   33520   18825
41786   33520   18825
42267   33520   18825
42747   33520   18825
43227   33520   18825
43708   33520   18825
44188   33520   18825
44668   33520   18825
45148   33520   18825
45629   33520   18825
46109   33520   18825
46589   33520   18825
47070   33520   18825
47550   33520   18825
>;
battery0_profile_t5_num = <100>;
battery0_profile_t5_col = <3>;
battery0_profile_t5 =
<
0       40810   11500
480     40360   11831
961     40116   12521
1441    39916   13061
1921    39693   13717
2402    39459   14528
2882    39235   15338
3362    39059   15916
3842    38913   16159
4323    38799   16214
4803    38698   16224
5283    38618   16200
5764    38540   16175
6244    38476   16175
6724    38427   16186
7205    38368   16175
7685    38320   16175
8165    38271   16211
8645    38232   16241
9126    38190   16237
9606    38158   16277
10086   38126   16334
10567   38097   16424
11047   38072   16521
11527   38050   16639
12008   38027   16788
12488   38003   16948
12968   37973   17158
13448   37951   17364
13929   37919   17490
14409   37887   17675
14889   37847   17876
15370   37813   18037
15850   37771   18197
16330   37723   18371
16811   37675   18571
17291   37619   18752
17771   37558   18936
18252   37500   19125
18732   37436   19261
19212   37372   19446
19692   37308   19606
20173   37244   19766
20653   37180   19901
21133   37131   20097
21614   37073   20250
22094   37025   20410
22574   36952   20556
23055   36867   20705
23535   36748   20865
24015   36562   21019
24495   36280   21160
24976   35832   21379
25456   35148   21747
25936   34071   20177
26417   33970   19925
26897   33970   19925
27377   33970   19925
27858   33970   19925
28338   33970   19925
28818   33970   19925
29298   33970   19925
29779   33970   19925
30259   33970   19925
30739   33970   19925
31220   33970   19925
31700   33970   19925
32180   33970   19925
32661   33970   19925
33141   33970   19925
33621   33970   19925
34102   33970   19925
34582   33970   19925
35062   33970   19925
35542   33970   19925
36023   33970   19925
36503   33970   19925
36983   33970   19925
37464   33970   19925
37944   33970   19925
38424   33970   19925
38905   33970   19925
39385   33970   19925
39865   33970   19925
40345   33970   19925
40826   33970   19925
41306   33970   19925
41786   33970   19925
42267   33970   19925
42747   33970   19925
43227   33970   19925
43708   33970   19925
44188   33970   19925
44668   33970   19925
45148   33970   19925
45629   33970   19925
46109   33970   19925
46589   33970   19925
47070   33970   19925
47550   33970   19925
>;
battery1_profile_t0_num = <100>;
battery1_profile_t0_col = <3>;
battery1_profile_t0 =
<
0       43220   900
480     43076   900
961     42934   900
1441    42806   900
1921    42689   911
2402    42567   901
2882    42455   925
3362    42333   900
3842    42221   900
4323    42113   911
4803    41997   901
5283    41893   925
5764    41780   918
6244    41677   922
6724    41566   925
7205    41464   925
7685    41352   925
8165    41248   925
8645    41145   948
9126    41039   925
9606    40943   950
10086   40840   932
10567   40741   950
11047   40645   950
11527   40552   964
12008   40484   1004
12488   40397   1006
12968   40261   959
13448   40133   975
13929   40037   989
14409   39985   1000
14889   39920   980
15370   39844   985
15850   39760   975
16330   39690   1000
16811   39612   1005
17291   39540   1025
17771   39463   1025
18252   39388   1051
18732   39318   1075
19212   39238   1075
19692   39150   1075
20173   39020   1003
20653   38877   950
21133   38780   950
21614   38696   925
22094   38625   925
22574   38566   925
23055   38508   925
23535   38460   925
24015   38411   925
24495   38353   925
24976   38314   925
25456   38268   925
25936   38228   943
26417   38184   933
26897   38152   950
27377   38109   939
27858   38077   950
28338   38037   931
28818   38003   934
29298   37971   950
29779   37949   975
30259   37917   975
30739   37884   955
31220   37862   975
31700   37840   1000
32180   37814   990
32661   37786   995
33141   37762   995
33621   37710   955
34102   37638   949
34582   37554   909
35062   37505   931
35542   37473   950
36023   37427   939
36503   37389   949
36983   37347   942
37464   37307   932
37944   37274   928
38424   37250   950
38905   37208   927
39385   37163   950
39865   37109   950
40345   37043   950
40826   36989   950
41306   36934   972
41786   36847   932
42267   36797   933
42747   36781   950
43227   36770   938
43708   36760   978
44188   36745   1000
44668   36719   1025
45148   36652   1049
45629   36402   1014
46109   35989   1025
46589   35455   1063
47070   34691   1084
47550   33540   1150
>;
battery1_profile_t1_num = <100>;
battery1_profile_t1_col = <3>;
battery1_profile_t1 =
<
0       43120   1150
480     42966   1150
961     42834   1175
1441    42714   1195
1921    42599   1189
2402    42487   1200
2882    42375   1200
3362    42263   1200
3842    42151   1200
4323    42043   1186
4803    41937   1176
5283    41829   1200
5764    41723   1207
6244    41618   1203
6724    41516   1225
7205    41405   1227
7685    41302   1233
8165    41198   1242
8645    41086   1225
9126    40989   1250
9606    40884   1231
10086   40804   1275
10567   40750   1333
11047   40712   1373
11527   40637   1361
12008   40501   1321
12488   40301   1281
12968   40114   1259
13448   39973   1275
13929   39866   1250
14409   39783   1250
14889   39726   1290
15370   39682   1310
15850   39660   1350
16330   39632   1360
16811   39572   1330
17291   39500   1330
17771   39433   1360
18252   39358   1375
18732   39288   1375
19212   39196   1350
19692   39091   1329
20173   38960   1267
20653   38837   1200
21133   38740   1167
21614   38666   1168
22094   38595   1150
22574   38541   1163
23055   38488   1152
23535   38433   1141
24015   38388   1168
24495   38342   1173
24976   38294   1162
25456   38256   1172
25936   38216   1168
26417   38174   1150
26897   38142   1173
27377   38109   1175
27858   38077   1175
28338   38045   1175
28818   38013   1175
29298   37981   1175
29779   37959   1200
30259   37928   1200
30739   37904   1200
31220   37876   1185
31700   37860   1225
32180   37834   1200
32661   37808   1200
33141   37784   1180
33621   37762   1200
34102   37719   1174
34582   37677   1150
35062   37645   1150
35542   37613   1150
36023   37581   1161
36503   37539   1150
36983   37507   1167
37464   37474   1150
37944   37442   1150
38424   37410   1162
38905   37368   1177
39385   37323   1183
39865   37259   1175
40345   37203   1198
40826   37149   1200
41306   37084   1200
41786   36997   1182
42267   36944   1200
42747   36921   1200
43227   36915   1212
43708   36898   1225
44188   36882   1244
44668   36859   1275
45148   36802   1299
45629   36582   1300
46109   36159   1308
46589   35617   1407
47070   34853   1470
47550   33730   1600
>;
battery1_profile_t2_num = <100>;
battery1_profile_t2_col = <3>;
battery1_profile_t2 =
<
0       42790   2375
480     42616   2420
961     42484   2500
1441    42364   2540
1921    42239   2536
2402    42128   2551
2882    42025   2575
3362    41916   2581
3842    41811   2600
4323    41709   2625
4803    41607   2650
5283    41493   2650
5764    41383   2632
6244    41278   2672
6724    41176   2675
7205    41075   2675
7685    40979   2658
8165    40899   2714
8645    40843   2838
9126    40795   2912
9606    40733   2925
10086   40622   2907
10567   40435   2776
11047   40211   2656
11527   40033   2600
12008   39902   2575
12488   39806   2575
12968   39727   2575
13448   39663   2598
13929   39614   2638
14409   39567   2653
14889   39535   2693
15370   39500   2700
15850   39451   2700
16330   39387   2700
16811   39310   2696
17291   39214   2656
17771   39110   2597
18252   38982   2526
18732   38860   2436
19212   38761   2400
19692   38681   2381
20173   38619   2384
20653   38561   2400
21133   38502   2375
21614   38452   2375
22094   38396   2375
22574   38358   2390
23055   38310   2375
23535   38262   2375
24015   38223   2400
24495   38184   2420
24976   38147   2400
25456   38110   2425
25936   38077   2425
26417   38045   2425
26897   38013   2425
27377   37981   2425
27858   37959   2425
28338   37933   2441
28818   37905   2443
29298   37881   2447
29779   37860   2475
30259   37839   2475
30739   37823   2492
31220   37807   2507
31700   37791   2548
32180   37775   2563
32661   37758   2625
33141   37733   2660
33621   37704   2708
34102   37672   2748
34582   37635   2813
35062   37597   2857
35542   37565   2937
36023   37530   3000
36503   37491   3071
36983   37448   3125
37464   37394   3182
37944   37337   3264
38424   37279   3344
38905   37221   3400
39385   37157   3504
39865   37081   3584
40345   37009   3645
40826   36976   3764
41306   36960   3899
41786   36938   4044
42267   36918   4204
42747   36894   4428
43227   36825   4653
43708   36675   4826
44188   36321   4897
44668   35789   5243
45148   35066   5744
45629   33910   6383
46109   33410   6625
46589   33410   6625
47070   33410   6625
47550   33410   6625
>;
battery1_profile_t3_num = <100>;
battery1_profile_t3_col = <3>;
battery1_profile_t3 =
<
0       42290   4675
480     42070   4795
961     41924   4990
1441    41796   5090
1921    41672   5135
2402    41550   5175
2882    41438   5230
3362    41323   5250
3842    41212   5270
4323    41101   5275
4803    41009   5326
5283    40934   5423
5764    40870   5531
6244    40806   5571
6724    40723   5589
7205    40595   5496
7685    40412   5376
8165    40200   5212
8645    40025   5132
9126    39888   5100
9606    39787   5124
10086   39697   5100
10567   39632   5138
11047   39574   5175
11527   39515   5187
12008   39467   5225
12488   39419   5242
12968   39361   5232
13448   39304   5250
13929   39235   5238
14409   39143   5200
14889   39049   5163
15370   38937   5092
15850   38825   5028
16330   38723   4975
16811   38643   4972
17291   38571   4950
17771   38505   4950
18252   38451   4974
18732   38393   4964
19212   38345   4975
19692   38297   4975
20173   38259   5009
20653   38211   5025
21133   38168   5025
21614   38136   5055
22094   38096   5075
22574   38062   5100
23055   38030   5100
23535   37992   5125
24015   37966   5155
24495   37934   5175
24976   37915   5211
25456   37899   5278
25936   37883   5358
26417   37870   5451
26897   37861   5589
27377   37845   5732
27858   37839   5905
28338   37823   6044
28818   37807   6229
29298   37791   6412
29779   37770   6587
30259   37748   6785
30739   37723   6962
31220   37693   7133
31700   37671   7317
32180   37629   7453
32661   37596   7610
33141   37555   7749
33621   37520   7909
34102   37472   8045
34582   37423   8181
35062   37365   8317
35542   37309   8477
36023   37245   8638
36503   37181   8773
36983   37117   8972
37464   37055   9172
37944   37014   9416
38424   36982   9652
38905   36960   9928
39385   36928   10208
39865   36891   10549
40345   36811   10868
40826   36666   11188
41306   36398   11438
41786   35984   11904
42267   35377   12660
42747   34472   13682
43227   33460   14675
43708   33460   14675
44188   33460   14675
44668   33460   14675
45148   33460   14675
45629   33460   14675
46109   33460   14675
46589   33460   14675
47070   33460   14675
47550   33460   14675
>;
battery1_profile_t4_num = <100>;
battery1_profile_t4_col = <3>;
battery1_profile_t4 =
<
0       41850   9125
480     41360   9576
961     41068   10431
1441    40916   10770
1921    40789   10861
2402    40667   10848
2882    40510   10736
3362    40319   10564
3842    40111   10387
4323    39940   10364
4803    39797   10294
5283    39693   10209
5764    39606   10275
6244    39535   10341
6724    39456   10300
7205    39376   10352
7685    39303   10341
8165    39227   10360
8645    39154   10344
9126    39074   10325
9606    38994   10297
10086   38907   10275
10567   38811   10192
11047   38715   10152
11527   38627   10122
12008   38544   10075
12488   38472   10056
12968   38416   10066
13448   38352   10026
13929   38303   10092
14409   38255   10129
14889   38206   10150
15370   38162   9995
15850   38130   10100
16330   38088   10225
16811   38056   10135
17291   38024   10235
17771   38006   10342
18252   37990   10510
18732   37980   10846
19212   37968   11030
19692   37952   11209
20173   37936   11405
20653   37920   11629
21133   37903   11842
21614   37894   12092
22094   37880   12354
22574   37855   12621
23055   37839   12891
23535   37823   13194
24015   37807   13444
24495   37791   13757
24976   37765   13978
25456   37739   14141
25936   37716   14165
26417   37694   14399
26897   37662   14542
27377   37629   14689
27858   37597   14761
28338   37565   15045
28818   37529   15134
29298   37481   15174
29779   37433   15239
30259   37385   15333
30739   37328   15395
31220   37274   15510
31700   37220   15575
32180   37156   15645
32661   37104   15760
33141   37056   15920
33621   37022   16101
34102   36989   16305
34582   36951   16489
35062   36910   16693
35542   36838   16855
36023   36711   17044
36503   36460   17180
36983   36017   17450
37464   35365   18050
37944   34392   18881
38424   33520   18825
38905   33520   18825
39385   33520   18825
39865   33520   18825
40345   33520   18825
40826   33520   18825
41306   33520   18825
41786   33520   18825
42267   33520   18825
42747   33520   18825
43227   33520   18825
43708   33520   18825
44188   33520   18825
44668   33520   18825
45148   33520   18825
45629   33520   18825
46109   33520   18825
46589   33520   18825
47070   33520   18825
47550   33520   18825
>;
battery1_profile_t5_num = <100>;
battery1_profile_t5_col = <3>;
battery1_profile_t5 =
<
0       40810   11500
480     40360   11831
961     40116   12521
1441    39916   13061
1921    39693   13717
2402    39459   14528
2882    39235   15338
3362    39059   15916
3842    38913   16159
4323    38799   16214
4803    38698   16224
5283    38618   16200
5764    38540   16175
6244    38476   16175
6724    38427   16186
7205    38368   16175
7685    38320   16175
8165    38271   16211
8645    38232   16241
9126    38190   16237
9606    38158   16277
10086   38126   16334
10567   38097   16424
11047   38072   16521
11527   38050   16639
12008   38027   16788
12488   38003   16948
12968   37973   17158
13448   37951   17364
13929   37919   17490
14409   37887   17675
14889   37847   17876
15370   37813   18037
15850   37771   18197
16330   37723   18371
16811   37675   18571
17291   37619   18752
17771   37558   18936
18252   37500   19125
18732   37436   19261
19212   37372   19446
19692   37308   19606
20173   37244   19766
20653   37180   19901
21133   37131   20097
21614   37073   20250
22094   37025   20410
22574   36952   20556
23055   36867   20705
23535   36748   20865
24015   36562   21019
24495   36280   21160
24976   35832   21379
25456   35148   21747
25936   34071   20177
26417   33970   19925
26897   33970   19925
27377   33970   19925
27858   33970   19925
28338   33970   19925
28818   33970   19925
29298   33970   19925
29779   33970   19925
30259   33970   19925
30739   33970   19925
31220   33970   19925
31700   33970   19925
32180   33970   19925
32661   33970   19925
33141   33970   19925
33621   33970   19925
34102   33970   19925
34582   33970   19925
35062   33970   19925
35542   33970   19925
36023   33970   19925
36503   33970   19925
36983   33970   19925
37464   33970   19925
37944   33970   19925
38424   33970   19925
38905   33970   19925
39385   33970   19925
39865   33970   19925
40345   33970   19925
40826   33970   19925
41306   33970   19925
41786   33970   19925
42267   33970   19925
42747   33970   19925
43227   33970   19925
43708   33970   19925
44188   33970   19925
44668   33970   19925
45148   33970   19925
45629   33970   19925
46109   33970   19925
46589   33970   19925
47070   33970   19925
47550   33970   19925
>;

/* battery_prop_dim2_ext.dtsi */
/*vboot voltage for gauge 0%*/
g_PMIC_MIN_VOL_row = <4>;
g_PMIC_MIN_VOL_col = <10>;
g_PMIC_MIN_VOL =
<
	32700  32700  32700  32700
	32700  32700  32700  32700
	32700  32700  32700  32700
	32200  32200  32200  32200
	31000  31000  31000  31000
	31500  31500  31500  31500
	31000  31000  31000  31000
	31000  31000  31000  31000
	31000  31000  31000  31000
	31000  31000  31000  31200
>;
/*boot_up current for gauge 0%*/
g_PON_SYS_IBOOT_row = <4>;
g_PON_SYS_IBOOT_col = <10>;
g_PON_SYS_IBOOT =
<
	5000  5000  5000  5000
	5000  5000  5000  5000
	5000  5000  5000  5000
	5000  5000  5000  5000
	5000  5000  5000  5000
	5000  5000  5000  5000
	5000  5000  5000  5000
	5000  5000  5000  5000
	5000  5000  5000  5000
	5000  5000  5000  5000
>;
/*Pseudo1 hide percentage*/
g_QMAX_SYS_VOL_row = <4>;
g_QMAX_SYS_VOL_col = <10>;
g_QMAX_SYS_VOL =
<
	33600  33600  33600  33600
	33600  33600  33600  33600
	33600  33600  33600  33600
	33600  33600  33600  33600
	33600  33600  33600  33600
	32500  32500  32500  32500
	32800  32800  32800  32800
	32800  32800  32800  32800
	32800  32800  32800  32800
	32800  32800  32800  32800
>;
/*Pseudo100 percentage setting*/
g_FG_PSEUDO100_row = <4>;
g_FG_PSEUDO100_col = <10>;
g_FG_PSEUDO100 =
<
	93  93  100  100
	93  93  100  100
	93  93  100  100
	93  93  100  100
	93  93  100  100
	93  93  100  100
	93  93  100  100
	100  100  100  100
	100  100  100  100
	100  100  100  100
>;

	};
};

/* /home/dpi/qb5_8814/workspace/P4_1716/android/kernel/kmodule/battery/fuelgauge/mtk_fuelgauge/mtk_fuelgauge.a13x_eur_open.dtsi */
&smd {
	bat_gm30: mtk_battery{
		CAR_TUNE_VALUE = <(100)>;
/*	Tune value for current measurement*/
		SHUTDOWN_1_TIME = <(100)>;
/*	If ui_soc shows 1% more than X minites, system will shutdown*/
	};
};

/* #include "../sti_abc.dtsi" */                     /* From sti_abc.py */
#ifndef CONFIG_SEC_FACTORY

#if 0
&${gpio_sub_connect_conn_parent} {
	sub_detect_conn_setting: sub-detect-conn-setting {
		samsung,pins = SEC_GPIO(${gpio_sub_connect_conn});
		samsung,pin-function = <0xf>;
		samsung,pin-pud = <0>;
		samsung,pin-drv = <0>;
	};
};
#endif

#if 0
&${gpio_sub_connect_conn_parent2} {
	sub_detect_conn_setting2: sub-detect-conn-setting2 {
		samsung,pins = SEC_GPIO(${gpio_sub_connect_conn2});
		samsung,pin-function = <0xf>;
		samsung,pin-pud = <0>;
		samsung,pin-drv = <0>;
	};
};
#endif

#if 0
&${gpio_cam_connect_conn_parent} {
	cam_detect_conn_setting: cam-detect-conn-setting {
		samsung,pins = SEC_GPIO(${gpio_cam_connect_conn});
		samsung,pin-function = <0xf>;
		samsung,pin-pud = <0>;
		samsung,pin-drv = <0>;
	};
};
#endif

#if 0
&${det_gpio_num_parent} {
	detect_conn_setting: detect_conn_setting {
		config {
#if 0
			pins = SEC_GPIO(${det_gpio_num_0}),
			       SEC_GPIO(${det_gpio_num_1}),
			       SEC_GPIO(${det_gpio_num_2}),
			       SEC_GPIO(${det_gpio_num_3}),
			       SEC_GPIO(${det_gpio_num_4}),
#if 0
			       SEC_GPIO(${det_gpio_num_5}),
			       SEC_GPIO(${det_gpio_num_6}),
			       SEC_GPIO(${det_gpio_num_7});
#elif 0
			       SEC_GPIO(${det_gpio_num_5}),
			       SEC_GPIO(${det_gpio_num_6});
#else
			       SEC_GPIO(${det_gpio_num_5});
#endif
#elif 0
			pins = SEC_GPIO(${det_gpio_num_0}),
			       SEC_GPIO(${det_gpio_num_1}),
			       SEC_GPIO(${det_gpio_num_2}),
			       SEC_GPIO(${det_gpio_num_3}),
#if 0
			       SEC_GPIO(${det_gpio_num_4}),
			       SEC_GPIO(${det_gpio_num_6}),
			       SEC_GPIO(${det_gpio_num_7});
#elif 0
			       SEC_GPIO(${det_gpio_num_4}),
			       SEC_GPIO(${det_gpio_num_6});
#else
			       SEC_GPIO(${det_gpio_num_4});
#endif
#elif 0
			pins = SEC_GPIO(${det_gpio_num_0}),
			       SEC_GPIO(${det_gpio_num_1}),
			       SEC_GPIO(${det_gpio_num_2}),
#if 0
			       SEC_GPIO(${det_gpio_num_3}),
			       SEC_GPIO(${det_gpio_num_6}),
			       SEC_GPIO(${det_gpio_num_7});
#elif 0
			       SEC_GPIO(${det_gpio_num_3}),
			       SEC_GPIO(${det_gpio_num_6});
#else
			       SEC_GPIO(${det_gpio_num_3});
#endif
#elif 0
			pins = SEC_GPIO(${det_gpio_num_0}),
			       SEC_GPIO(${det_gpio_num_1}),
#if 0
			       SEC_GPIO(${det_gpio_num_2}),
			       SEC_GPIO(${det_gpio_num_6}),
			       SEC_GPIO(${det_gpio_num_7});
#elif 0
			       SEC_GPIO(${det_gpio_num_2}),
			       SEC_GPIO(${det_gpio_num_6});
#else
			       SEC_GPIO(${det_gpio_num_2});
#endif
#elif 0
			pins = SEC_GPIO(${det_gpio_num_0}),
#if 0
			       SEC_GPIO(${det_gpio_num_1}),
			       SEC_GPIO(${det_gpio_num_6}),
			       SEC_GPIO(${det_gpio_num_7});
#elif 0
			       SEC_GPIO(${det_gpio_num_1}),
			       SEC_GPIO(${det_gpio_num_6});
#else
			       SEC_GPIO(${det_gpio_num_1});
#endif
#elif 0
			pins =
#if 0
			       SEC_GPIO(${det_gpio_num_0}),
			       SEC_GPIO(${det_gpio_num_6}),
			       SEC_GPIO(${det_gpio_num_7});
#elif 0
			       SEC_GPIO(${det_gpio_num_0}),
			       SEC_GPIO(${det_gpio_num_6});
#else
			       SEC_GPIO(${det_gpio_num_0});
#endif
#elif 0
			pins = SEC_GPIO(${det_gpio_num_6}),
			       SEC_GPIO(${det_gpio_num_7});
#elif 0
			pins = SEC_GPIO(${det_gpio_num_6});
#endif
			drive-strength = <2>;
			bias-disable; /*NO PULL*/
			input-enable;
		};
	};
};
#endif /*use_dynamic_ap_gpio_detect*/

#if 0
&${det_pm_gpio_num_parent} {
	detect_conn_pm_setting: detect_conn_pm_setting {
#if 0 && 0
		pins = SEC_GPIO(${det_pm_gpio_num_0}),
		       SEC_GPIO(${det_pm_gpio_num_1});
#elif 0
		pins = SEC_GPIO(${det_pm_gpio_num_0});
#elif 0
		pins = SEC_GPIO(${det_pm_gpio_num_1});
#endif
		function = "normal";
		power-source = <0>;
		bias-disable; /*NO PULL*/
		input-enable;
	};
};
#endif /*use_dynamic_pm_gpio_detect*/

#endif /* not CONFIG_SEC_FACTORY */

&smd {
	sec_abc {
		compatible = "samsung,sec_abc";
		status = "okay";

		gpu {
			gpu,label="GPU fault";
#if 0
			gpu,threshold_count=<4>;
			gpu,threshold_time=<1200>;
#else
			gpu,threshold_count=<20>;
			gpu,threshold_time=<1200>;
#endif
		};
#if 0
		gpu_page {
			gpu_page,label="GPU page fault";
			gpu_page,threshold_count=<20>;
			gpu_page,threshold_time=<1200>;
		};
#endif
		aicl {
			aicl,label="battery aicl";
			aicl,threshold_count=<5>;
			aicl,threshold_time=<300>;
		};
#if 0
		motto {
			motto,label="motto info base";
			motto,info_bootcheck_base = <0x15860858>;
			motto,info_device_base = <0x1586085C>;
		};
#endif
	};
	abc_hub {
		compatible = "samsung,abc_hub";
		status = "okay";

#ifndef CONFIG_SEC_FACTORY
#if 0
#if 0 && 0
		pinctrl-names = "det_ap_connect","det_pm_connect";
		pinctrl-0 = <&detect_conn_setting>;
		pinctrl-1 = <&detect_conn_pm_setting>;
#elif 0
		pinctrl-names = "det_ap_connect";
		pinctrl-0 = <&detect_conn_setting>;
#elif 0
		pinctrl-names = "det_pm_connect";
		pinctrl-0 = <&detect_conn_pm_setting>;
#endif
/*not feature_abc_qcom_dt*/
#elif 0 && 0 && 0
		pinctrl-0 = <&sub_detect_conn_setting &sub_detect_conn_setting2 &cam_detect_conn_setting>;
#elif 0 && 0
		pinctrl-0 = <&sub_detect_conn_setting &cam_detect_conn_setting>;
#elif 0 && 0
		pinctrl-0 = <&sub_detect_conn_setting &sub_detect_conn_setting2>;
#elif 0
		pinctrl-0 = <&sub_detect_conn_setting>;
#elif 0
		pinctrl-0 = <&cam_detect_conn_setting>;
#endif
#endif /* not CONFIG_SEC_FACTORY */
		bootc {
			bootc,time_spec_user = <100000>; /* user binary user build */
			bootc,time_spec_eng = <150000>; /* user binary eng build */
			bootc,time_spec_fac = <100000>; /* factory binary */
		};

#ifndef CONFIG_SEC_FACTORY
#if 0
#if 0 || 0
		cond {
#if 0
			sec,det_conn_gpios = <
#if 0
					SEC_GPIO_REF(${det_gpio_num_0}) 0
#endif
#if 0
					SEC_GPIO_REF(${det_gpio_num_1}) 0
#endif
#if 0
					SEC_GPIO_REF(${det_gpio_num_2}) 0
#endif
#if 0
					SEC_GPIO_REF(${det_gpio_num_3}) 0
#endif
#if 0
					SEC_GPIO_REF(${det_gpio_num_4}) 0
#endif
#if 0
					SEC_GPIO_REF(${det_gpio_num_5}) 0
#endif
#if 0
					SEC_GPIO_REF(${det_gpio_num_6}) 0
#endif
#if 0
					SEC_GPIO_REF(${det_gpio_num_7}) 0
#endif
					>;
#if 0 || 0
			sec,det_conn_name =
#endif
#if 0 && 0
					"", "", "", "", "", "",
					"", "";
#elif 0
					"", "", "", "", "", "";
#elif 0
					"", "";
#endif
#endif /*use_dynamic_ap_gpio_detect*/

#if 0
			sec,det_pm_conn_gpios = <
#if 0
					SEC_GPIO_REF(${det_pm_gpio_num_0}) 0
#endif
#if 0
					SEC_GPIO_REF(${det_pm_gpio_num_1}) 0
#endif
					>;
#if 0 || 0
			sec,det_pm_conn_name =
#endif
#if 0 && 0
					"",
					"";
#elif 0
					"";
#elif 0
					"";
#endif
#endif /*use_dynamic_pm_gpio_detect */
		};
#endif /*use_dynamic_ap_gpio_detect || use_dynamic_pm_gpio_detect*/

/*not feature_abc_qcom_dt, feature_abc_lsi_dt*/
#elif 0 && 0 && 0
		cond {
			sec,det_conn_gpios = <SEC_GPIO_REF(${gpio_sub_connect_conn}) 0
						SEC_GPIO_REF(${gpio_sub_connect_conn2}) 0
						SEC_GPIO_REF(${gpio_cam_connect_conn}) 0>;
			sec,det_conn_name = "sub", "sub2", "cam";
			sec,det_conn_irq_type = <3>; /* BOTH EDGE */
		};
#elif 0 && 0
		cond {
			sec,det_conn_gpios = <SEC_GPIO_REF(${gpio_sub_connect_conn}) 0
						SEC_GPIO_REF(${gpio_cam_connect_conn}) 0>;
			sec,det_conn_name = "sub", "cam";
			sec,det_conn_irq_type = <3>; /* BOTH EDGE */
		};
#elif 0 && 0
		cond {
			sec,det_conn_gpios = <SEC_GPIO_REF(${gpio_sub_connect_conn}) 0
						SEC_GPIO_REF(${gpio_sub_connect_conn2}) 0>;
			sec,det_conn_name = "sub", "sub2";
			sec,det_conn_irq_type = <3>; /* BOTH EDGE */
		};
#elif 0
		cond {
			sec,det_conn_gpios = <SEC_GPIO_REF(${gpio_sub_connect_conn}) 0>;
			sec,det_conn_name = "sub";
			sec,det_conn_irq_type = <3>; /* BOTH EDGE */
		};
#elif 0
		cond {
			sec,det_conn_gpios = <SEC_GPIO_REF(${gpio_cam_connect_conn}) 0>;
			sec,det_conn_name = "cam";
			sec,det_conn_irq_type = <3>; /* BOTH EDGE */
		};
#endif
#endif /* not CONFIG_SEC_FACTORY */
	};
};

/* #include "../sec_pinctrl_wrapper.dtsi" */         /* From sec_pinctrl_wrapper.py */
#define PIN_FUNC_INPUT		input-enable
#define PIN_FUNC_INPUT_WAKEUP	input-enable
#define PIN_FUNC_OUTPUT		output-enable
#define PIN_FUNC_OUTPUT_HIGH		output-high
#define PIN_FUNC_OUTPUT_LOW		output-low

#define PIN_PULL_NONE	bias-disable
#define PIN_PULL_DOWN	bias-pull-down
#define PIN_PULL_UP	bias-pull-up
#define PIN_PULL_OPEN	bias-high-impedance

/*
 * MTK_DRIVE_2mA  2
 * MTK_DRIVE_4mA  4
 * MTK_DRIVE_6mA  6
 * MTK_DRIVE_8mA  8
 * MTK_DRIVE_10mA 10
 * MTK_DRIVE_12mA 12
 * MTK_DRIVE_14mA 14
 * MTK_DRIVE_16mA 16
 */

#define PIN_DRV_LV1	2
#define PIN_DRV_LV2	4
#define PIN_DRV_LV3	6
#define PIN_DRV_LV4	8
#define PIN_DRV_LV5	10
#define PIN_DRV_LV6	12
#define PIN_DRV_LV7	14
#define PIN_DRV_LV8	16

#define PIN_EXPAND(pin) #pin

#define SEC_GPIO(src, type, num)	PIN_EXPAND(gpio##num)
#define SEC_GPIO_REF(src, type, num)	&type num
#define SEC_GPIO_NUM(src, type, num)	num
#define SEC_GPIO_TYPE(src, type, num)	&type
#define SEC_GPIO_PHANDLE_ACTIVE(src, type, num)	SEC_GPIO_PHANDLE(type, num, active)
#define SEC_GPIO_PHANDLE_SLEEP(src, type, num)	SEC_GPIO_PHANDLE(type, num, sleep)
#define SEC_GPIO_PHANDLE(type, num, mode)	type##_##num##_##mode

#define MTK_PINMUX(gpio, func) (MTK_PIN_NO(gpio) | func)

#define GPIO_CONFIG(_src, _type, _num, _func)		\
	pins_cmd_dat{					\
		pinmux = <MTK_PINMUX(SEC_GPIO_NUM(_src, _type, _num), 0)>;	\
		PIN_ ##_func;		\
	}

#define GPIO_CONFIG_PUD(_src, _type, _num, _func, _pull)	\
	pins_cmd_dat{					\
		pinmux = <MTK_PINMUX(SEC_GPIO_NUM(_src, _type, _num), 0)>;	\
		PIN_ ##_pull;				\
		PIN_ ##_func;		\
	}

#define GPIO_CONFIG_PUD_DRV(_src, _type, _num, _func, _pull, _drv)	\
	pins_cmd_dat{					\
		pinmux = <MTK_PINMUX(SEC_GPIO_NUM(_src, _type, _num), 0)>;	\
		PIN_ ##_pull;				\
		PIN_ ##_func;		\
		drive-strength = <PIN_ ##_drv>;	\
	}

#define SEC_ADC(type, num) <&type num>
#define SEC_ADC_OPT(type, num) ,<&type num>
#define SEC_ADC_NUM(type, num) <num>

/* #include "../input_booster.dtsi" */               /* From input_booster.py */
/* Copyright (c) 2019, The Linux Foundation. All rights reserved.
 *
 * This program is free software; you can redistribute it and/or modify
 * it under the terms of the GNU General Public License version 2 and
 * only version 2 as published by the Free Software Foundation.
 *
 * This program is distributed in the hope that it will be useful,
 * but WITHOUT ANY WARRANTY; without even the implied warranty of
 * MERCHANTABILITY or FITNESS FOR A PARTICULAR PURPOSE.  See the
 * GNU General Public License for more details.
 */

&smd {
	input_booster {
		status = "okay";
		compatible = "input_booster";
		resValcount = "2";
		max_resource_count = "3";
		max_cluster_count = "3";
		#address-cells = <1>;
		#size-cells = <0>;

		/* Each Cpu Cluster Start Cpu */
		cpu_cluster_policy = "6,0";

		/* < CPU, DDR, SCHEDBOOST > */
		ib_release_values = "-1,16,0";

		/* Select Allowed Resource Index Group */
		allowed_resources = "0,1";

		booster_key@1 {
			input_booster,label = "key";
			input_booster,type = <0>;	/* BOOSTER_DEVICE_KEY */

			/* Time table */
			input_booster,head_time = <200>;
			input_booster,tail_time = <0>;

			/* Resource Table Sequentially identified with index
			 * CPU's ID & Index : 0
			 * DDR's ID & Index : 1
			*/

			/* Input Booster Resource Frequency */
			inputbooster,resource {
				compatible = "resource";
				resource@1 {
					resource,label = "CPU";
					resource,value = <1274000 0>;
				};

				resource@2 {
					resource,label = "DDR";
					resource,value = <0 0>;
				};
			};
		};

		booster_key@2 {
			input_booster,label = "touchkey";
			input_booster,type = <1>;	/* BOOSTER_DEVICE_TOUCHKEY */

			/* Time table */
			input_booster,head_time = <1>;
			input_booster,tail_time = <300>;

			/* Input Booster Resource Frequency */
			inputbooster,resource {
				compatible = "resource";
				resource@1 {
					resource,label = "CPU";
					resource,value = <0 1042000>;
				};

				resource@2 {
					resource,label = "DDR";
					resource,value = <0 0>;
				};
			};
		};

		booster_key@3 {
			input_booster,label = "touch";
			input_booster,type = <2>;	/* BOOSTER_DEVICE_TOUCH */

			/* Time table */
			input_booster,head_time = <130>;
			input_booster,tail_time = <500>;

			/* Input Booster Resource Frequency */
			inputbooster,resource {
				compatible = "resource";
				resource@1 {
					resource,label = "CPU";
					resource,value = <1274000 1042000>;
				};

				resource@2 {
					resource,label = "DDR";
					resource,value = <4266 4266>;
				};
			};
		};

		booster_key@4 {
			input_booster,label = "multitouch";
			input_booster,type = <3>;	/* BOOSTER_DEVICE_MULTITOUCH */

			/* Time table */
			input_booster,head_time = <1000>;
			input_booster,tail_time = <500>;

			/* Input Booster Resource Frequency */
			inputbooster,resource {
				compatible = "resource";
				resource@1 {
					resource,label = "CPU";
					resource,value = <1534000 1274000>;
				};

				resource@2 {
					resource,label = "DDR";
					resource,value = <0 0>;
				};
			};
		};

		booster_key@5 {
			input_booster,label = "keyboard";
			input_booster,type = <4>;	/* BOOSTER_DEVICE_KEYBOARD */

			/* Time table */
			input_booster,head_time = <130>;
			input_booster,tail_time = <130>;

			/* Input Booster Resource Frequency */
			inputbooster,resource {
				compatible = "resource";
				resource@1 {
					resource,label = "CPU";
					resource,value = <1042000 1042000>;
				};

				resource@2 {
					resource,label = "DDR";
					resource,value = <0 0>;
				};
			};
		};

		booster_key@6 {
			input_booster,label = "MOUSE";
			input_booster,type = <5>;	/* BOOSTER_DEVICE_MOUSE */

			/* Time table */
			input_booster,head_time = <200>;
			input_booster,tail_time = <300>;

			/* Input Booster Resource Frequency */
			inputbooster,resource {
				compatible = "resource";
				resource@1 {
					resource,label = "CPU";
					resource,value = <1274000 1042000>;
				};

				resource@2 {
					resource,label = "DDR";
					resource,value = <0 0>;
				};
			};
		};

		booster_key@7 {
			input_booster,label = "mouse_wheel";
			input_booster,type = <6>;	/* BOOSTER_DEVICE_MOUSE */

			/* Time table */
			input_booster,head_time = <200>;
			input_booster,tail_time = <0>;

			/* Input Booster Resource Frequency */
			inputbooster,resource {
				compatible = "resource";
				resource@1 {
					resource,label = "CPU";
					resource,value = <1274000 0>;
				};

				resource@2 {
					resource,label = "DDR";
					resource,value = <0 0>;
				};
			};
		};

		booster_key@8 {
			input_booster,label = "pen_hover";
			input_booster,type = <7>;	/* BOOSTER_DEVICE_MOUSE */

			/* Time table */
			input_booster,head_time = <200>;
			input_booster,tail_time = <300>;

			/* Input Booster Resource Frequency */
			inputbooster,resource {
				compatible = "resource";
				resource@1 {
					resource,label = "CPU";
					resource,value = <1274000 1042000>;
				};

				resource@2 {
					resource,label = "DDR";
					resource,value = <0 0>;
				};
			};
		};

		booster_key@9 {
			input_booster,label = "pen";
			input_booster,type = <8>;	/* BOOSTER_DEVICE_MOUSE */

			/* Time table */
			input_booster,head_time = <200>;
			input_booster,tail_time = <600>;

			/* Input Booster Resource Frequency */
			inputbooster,resource {
				compatible = "resource";
				resource@1 {
					resource,label = "CPU";
					resource,value = <1719000 1042000>;
				};

				resource@2 {
					resource,label = "DDR";
					resource,value = <0 0>;
				};
			};
		};
		/* If you need to add new key type, add it this position */
	};
};

/* #include "../vibrator_vib_info.dtsi" */           /* From vibrator_vib_info.py */

&smd {
	vib_info: vibrator_info {
		status = "okay";
		compatible = "samsung,vib-info";
		functions = "";
#if 0
		samsung,intensities = <>;
#else
		samsung,intensities = <>;
#endif

#if 0
		samsung,haptic_intensities = <>;
#else
		samsung,haptic_intensities = <>;
#endif
	};
};

/* #include "../ap_mtk_mt6833.dtsi" */               /* From ap_mtk_mt6833.py */
#include <dt-bindings/clock/mt6833-clk.h>

#define topckgen_clk topckgen
#define infracfg_ao_clk infracfg_ao
/* /home/dpi/qb5_8814/workspace/P4_1716/android/kernel/kmodule/ap/mtk/mt6833/ap_mtk_mt6833.a13x_eur.12.dtsi */
#include "../../mediatek/k6833v1_64_titan_hinterwald/Board_00.dts"
#include "../../mediatek/k6833v1_64_titan_hinterwald/gpio_12_eur.dtsi"

/* #include "../gpio_sec_detect_conn.dtsi" */        /* From gpio_sec_detect_conn.py */
#ifdef CONFIG_SEC_FACTORY
#if 1
&pio {
	detect_conn_setting: detect_conn_setting {
		config {
#if 0
			pinmux = <MTK_PINMUX(SEC_GPIO_NUM(AP,pio,19), 0)>,
			       <MTK_PINMUX(SEC_GPIO_NUM(${det_gpio_num_1}), 0)>,
			       <MTK_PINMUX(SEC_GPIO_NUM(${det_gpio_num_2}), 0)>,
			       <MTK_PINMUX(SEC_GPIO_NUM(${det_gpio_num_3}), 0)>,
			       <MTK_PINMUX(SEC_GPIO_NUM(${det_gpio_num_4}), 0)>,
#if 0
			       <MTK_PINMUX(SEC_GPIO_NUM(${det_gpio_num_5}), 0)>,
			       <MTK_PINMUX(SEC_GPIO_NUM(${det_gpio_num_6}), 0)>,
			       <MTK_PINMUX(SEC_GPIO_NUM(${det_gpio_num_7}), 0)>;
#elif 0
			       <MTK_PINMUX(SEC_GPIO_NUM(${det_gpio_num_5}), 0)>,
			       <MTK_PINMUX(SEC_GPIO_NUM(${det_gpio_num_6}), 0)>;
#else
			       <MTK_PINMUX(SEC_GPIO_NUM(${det_gpio_num_5}), 0)>;
#endif
#elif 0
			pinmux = <MTK_PINMUX(SEC_GPIO_NUM(AP,pio,19), 0)>,
			       <MTK_PINMUX(SEC_GPIO_NUM(${det_gpio_num_1}), 0)>,
			       <MTK_PINMUX(SEC_GPIO_NUM(${det_gpio_num_2}), 0)>,
			       <MTK_PINMUX(SEC_GPIO_NUM(${det_gpio_num_3}), 0)>,
#if 0
			       <MTK_PINMUX(SEC_GPIO_NUM(${det_gpio_num_4}), 0)>,
			       <MTK_PINMUX(SEC_GPIO_NUM(${det_gpio_num_6}), 0)>,
			       <MTK_PINMUX(SEC_GPIO_NUM(${det_gpio_num_7}), 0)>;
#elif 0
			       <MTK_PINMUX(SEC_GPIO_NUM(${det_gpio_num_4}), 0)>,
			       <MTK_PINMUX(SEC_GPIO_NUM(${det_gpio_num_6}), 0)>;
#else
			       <MTK_PINMUX(SEC_GPIO_NUM(${det_gpio_num_4}), 0)>;
#endif
#elif 0
			pinmux = <MTK_PINMUX(SEC_GPIO_NUM(AP,pio,19), 0)>,
			       <MTK_PINMUX(SEC_GPIO_NUM(${det_gpio_num_1}), 0)>,
			       <MTK_PINMUX(SEC_GPIO_NUM(${det_gpio_num_2}), 0)>,
#if 0
			       <MTK_PINMUX(SEC_GPIO_NUM(${det_gpio_num_3}), 0)>,
			       <MTK_PINMUX(SEC_GPIO_NUM(${det_gpio_num_6}), 0)>,
			       <MTK_PINMUX(SEC_GPIO_NUM(${det_gpio_num_7}), 0)>;
#elif 0
			       <MTK_PINMUX(SEC_GPIO_NUM(${det_gpio_num_3}), 0)>,
			       <MTK_PINMUX(SEC_GPIO_NUM(${det_gpio_num_6}), 0)>;
#else
			       <MTK_PINMUX(SEC_GPIO_NUM(${det_gpio_num_3}), 0)>;
#endif
#elif 0
			pinmux = <MTK_PINMUX(SEC_GPIO_NUM(AP,pio,19), 0)>,
			       <MTK_PINMUX(SEC_GPIO_NUM(${det_gpio_num_1}), 0)>,
#if 0
			       <MTK_PINMUX(SEC_GPIO_NUM(${det_gpio_num_2}), 0)>,
			       <MTK_PINMUX(SEC_GPIO_NUM(${det_gpio_num_6}), 0)>,
			       <MTK_PINMUX(SEC_GPIO_NUM(${det_gpio_num_7}), 0)>;
#elif 0
			       <MTK_PINMUX(SEC_GPIO_NUM(${det_gpio_num_2}), 0)>,
			       <MTK_PINMUX(SEC_GPIO_NUM(${det_gpio_num_6}), 0)>;
#else
			       <MTK_PINMUX(SEC_GPIO_NUM(${det_gpio_num_2}), 0)>;
#endif
#elif 0
			pinmux = <MTK_PINMUX(SEC_GPIO_NUM(AP,pio,19), 0)>,
#if 0
			       <MTK_PINMUX(SEC_GPIO_NUM(${det_gpio_num_1}), 0)>,
			       <MTK_PINMUX(SEC_GPIO_NUM(${det_gpio_num_6}), 0)>,
			       <MTK_PINMUX(SEC_GPIO_NUM(${det_gpio_num_7}), 0)>;
#elif 0
			       <MTK_PINMUX(SEC_GPIO_NUM(${det_gpio_num_1}), 0)>,
			       <MTK_PINMUX(SEC_GPIO_NUM(${det_gpio_num_6}), 0)>;
#else
			       <MTK_PINMUX(SEC_GPIO_NUM(${det_gpio_num_1}), 0)>;
#endif
#elif 1
			pinmux =
#if 0
			       <MTK_PINMUX(SEC_GPIO_NUM(AP,pio,19), 0)>,
			       <MTK_PINMUX(SEC_GPIO_NUM(${det_gpio_num_6}), 0)>,
			       <MTK_PINMUX(SEC_GPIO_NUM(${det_gpio_num_7}), 0)>;
#elif 0
			       <MTK_PINMUX(SEC_GPIO_NUM(AP,pio,19), 0)>,
			       <MTK_PINMUX(SEC_GPIO_NUM(${det_gpio_num_6}), 0)>;
#else
			       <MTK_PINMUX(SEC_GPIO_NUM(AP,pio,19), 0)>;
#endif
#elif 0
			pinmux = <MTK_PINMUX(SEC_GPIO_NUM(${det_gpio_num_6}), 0)>,
			       <MTK_PINMUX(SEC_GPIO_NUM(${det_gpio_num_7}), 0)>;
#elif 0
			pinmux = <MTK_PINMUX(SEC_GPIO_NUM(${det_gpio_num_6}), 0)>;
#endif
			drive-strength = <2>;
			bias-disable; /*NO PULL*/
			input-enable;
		};
	};
};
#endif /*use_dynamic_ap_gpio_detect*/

#if 0
&${det_pm_gpio_num_parent} {
	detect_conn_pm_setting: detect_conn_pm_setting {
#if 0 && 0
		pinmux = <MTK_PINMUX(SEC_GPIO_NUM(${det_pm_gpio_num_0}), 0)>,
		       <MTK_PINMUX(SEC_GPIO_NUM(${det_pm_gpio_num_1}), 0)>;
#elif 0
		pinmux = <MTK_PINMUX(SEC_GPIO_NUM(${det_pm_gpio_num_0}), 0)>;
#elif 0
		pinmux = <MTK_PINMUX(SEC_GPIO_NUM(${det_pm_gpio_num_1}), 0)>;
#endif
		function = "normal";
		power-source = <0>;
		bias-disable; /*NO PULL*/
		input-enable;
	};
};
#endif /*use_dynamic_pm_gpio_detect*/

&smd {
	sec_detect_conn {
		compatible = "samsung,sec_detect_conn";
		status = "okay";

#if 1
		sec,det_conn_gpios = <
#if 1
					SEC_GPIO_REF(AP,pio,19) 0
#endif
#if 0
					SEC_GPIO_REF(${det_gpio_num_1}) 0
#endif
#if 0
					SEC_GPIO_REF(${det_gpio_num_2}) 0
#endif
#if 0
					SEC_GPIO_REF(${det_gpio_num_3}) 0
#endif
#if 0
					SEC_GPIO_REF(${det_gpio_num_4}) 0
#endif
#if 0
					SEC_GPIO_REF(${det_gpio_num_5}) 0
#endif
#if 0
					SEC_GPIO_REF(${det_gpio_num_6}) 0
#endif
#if 0
					SEC_GPIO_REF(${det_gpio_num_7}) 0
#endif
					>;
#if 1 || 0
		sec,det_conn_name =
#endif
#if 1
					"SUB_CONNECT"
#endif
#if 0
					,""
#endif
#if 0
					,""
#endif
#if 0
					,""
#endif
#if 0
					,""
#endif
#if 0
					,""
#endif
#if 0
					,""
#endif
#if 0
					,""
#endif
#if 1 || 0
;
#endif
#endif /*use_dynamic_ap_gpio_detect*/

#if 0
		sec,det_pm_conn_gpios = <
#if 0
					SEC_GPIO_REF(${det_pm_gpio_num_0}) 0
#endif
#if 0
					SEC_GPIO_REF(${det_pm_gpio_num_1}) 0
#endif
					>;
#if 0 || 0
		sec,det_pm_conn_name =
#endif
#if 0 && 0
					"", "";
#elif 0
					"";
#elif 0
					"";
#endif
#endif /*use_dynamic_pm_gpio_detect*/

#if 1 && 0
		pinctrl-names = "det_ap_connect","det_pm_connect";
		pinctrl-0 = <&detect_conn_setting>;
		pinctrl-1 = <&detect_conn_pm_setting>;
#elif 1
		pinctrl-names = "det_ap_connect";
		pinctrl-0 = <&detect_conn_setting>;
#elif 0
		pinctrl-names = "det_pm_connect";
		pinctrl-0 = <&detect_conn_pm_setting>;
#endif
	};
};
#endif /* CONFIG_SEC_FACTORY */


/* #include "../sensorhub_mt6833_shub.dtsi" */       /* From sensorhub_mt6833_shub.py */
/ {
	fragment@model {
		target-path = "/";
		__overlay__ {
			shub {
				compatible = "shub";
			};
		};
	};
};

/* /home/dpi/qb5_8814/workspace/P4_1716/android/kernel/kmodule/sensorhub/mtk/mt6833_shub/dts/sensorhub_mt6833_shub.a13x.dtsi */
/ {
	fragment@model {
		target-path = "/";
		__overlay__ {
			shub {
				acc-motor-coef = <20>;
				acc-lsm6dsl-position = <0>;
				mag-ak09918c-position = <2>;
				mag-ak09918c-array = /bits/ 8 <177 79 157 243 91 230 0 231 213
								53 96 91 195 228 254 215 255 63
								50 22 190 249 154 52 11 231 251>;
			};
		};
	};
};

/* /home/dpi/qb5_8814/workspace/P4_1716/android/kernel/kmodule/sensorhub/mtk/mt6833_shub/dts/sensorhub_mt6833_shub.a13x.04.dtsi */
/ {
	fragment@model {
		target-path = "/";
		__overlay__ {
			shub {
				mag-ak09918c-array = /bits/ 8 <177 79 157 243 91 230 0 231 213
								53 96 91 195 228 254 215 255 63
								50 22 190 249 154 52 11 231 251>;
			};
		};
	};
};

/* #include "../input_nt36523_spi.dtsi" */           /* From input_nt36523_spi.py */
/* NEED TO FIX IF YOU WANT USE THIS */

&pio {
	nt36523_tsp_intr_on: nt36523_tsp_intr_on {
		pins_cmd_dat {
			pinmux = <MTK_PINMUX(SEC_GPIO_NUM(AP,pio,14), 0)>;
			slew-rate = <0>;
			bias-disable;
		};
	};

	nt36523_tsp_intr_off: nt36523_tsp_intr_off {
		pins_cmd_dat {
			pinmux = <MTK_PINMUX(SEC_GPIO_NUM(AP,pio,14), 0)>;
			slew-rate = <0>;
			input-enable;
			bias-pull-down;
		};
	};
};
&pio {
	nt36523_tsp_reset_on: nt36523_tsp_reset_on {
		pins_cmd_dat{
			pinmux = <MTK_PINMUX(SEC_GPIO_NUM(AP,pio,7), 0)>;
			slew-rate = <1>;
			bias-disable;
			output-high;
		};
	};

	nt36523_tsp_reset_off: nt36523_tsp_reset_off {
		pins_cmd_dat{
			pinmux = <MTK_PINMUX(SEC_GPIO_NUM(AP,pio,7), 0)>;
			slew-rate = <1>;
			bias-disable;
			output-low;
		};
	};
};
&pio {
	nt36523_tsp_on_cs: nt36523_tsp_on_cs {
		pins_cmd_dat{
			pinmux = <MTK_PINMUX(SEC_GPIO_NUM(AP,pio,28), 1)>;
			bias-disable;
		};
	};
	nt36523_tsp_off_cs: nt36523_tsp_off_cs {
		pins_cmd_dat{
			pinmux = <MTK_PINMUX(SEC_GPIO_NUM(AP,pio,28), 0)>;
			slew-rate = <1>;
			bias-disable;
			output-low;
		};
	};
};
&pio {
	nt36523_tsp_on_clk: nt36523_tsp_on_clk {
		pins_cmd_dat{
			pinmux = <MTK_PINMUX(SEC_GPIO_NUM(AP,pio,27), 1)>;
			bias-disable;
		};
	};
	nt36523_tsp_off_clk: nt36523_tsp_off_clk {
		pins_cmd_dat{
			pinmux = <MTK_PINMUX(SEC_GPIO_NUM(AP,pio,27), 0)>;
			slew-rate = <1>;
			bias-disable;
			output-low;
		};
	};

	nt36523_tsp_on_mosi: nt36523_tsp_on_mosi {
		pins_cmd_dat{
			pinmux = <MTK_PINMUX(SEC_GPIO_NUM(AP,pio,29), 1)>;
			bias-disable;
		};
	};
	nt36523_tsp_off_mosi: nt36523_tsp_off_mosi {
		pins_cmd_dat{
			pinmux = <MTK_PINMUX(SEC_GPIO_NUM(AP,pio,29), 0)>;
			slew-rate = <1>;
			bias-disable;
			output-low;
		};
	};

	nt36523_tsp_on_miso: nt36523_tsp_on_miso {
		pins_cmd_dat{
			pinmux = <MTK_PINMUX(SEC_GPIO_NUM(AP,pio,30), 1)>;
			bias-disable;
		};
	};

	nt36523_tsp_off_miso: nt36523_tsp_off_miso {
		pins_cmd_dat{
			pinmux = <MTK_PINMUX(SEC_GPIO_NUM(AP,pio,30), 0)>;
			slew-rate = <0>;
			bias-pull-down;
			input-enable;
		};
	};

	nt36523_default_miso: nt36523_default_miso {
		pins_cmd_dat{
			pinmux = <MTK_PINMUX(SEC_GPIO_NUM(AP,pio,30), 0)>;
			slew-rate = <0>;
			bias-disable;
			output-low;
		};
	};
};

&spi1 {
	status = "okay";
	#address-cells = <1>;
	#size-cells = <0>;
	num-cs = <1>;
	tsp_novatek: novatek@2 {
		status = "okay";
		compatible = "novatek,NVT-ts-spi";
		reg = <2>; //Same as CS ID
		spi-max-frequency = <9600000>;

		pinctrl-names = "default", "on_state", "off_state";
		pinctrl-0 = <&nt36523_tsp_intr_on &nt36523_tsp_reset_on &nt36523_tsp_on_cs &nt36523_tsp_on_clk &nt36523_tsp_on_mosi &nt36523_tsp_on_miso>;
		pinctrl-1 = <&nt36523_tsp_intr_on &nt36523_tsp_reset_on &nt36523_tsp_on_cs &nt36523_tsp_on_clk &nt36523_tsp_on_mosi &nt36523_tsp_on_miso>;
		pinctrl-2 = <&nt36523_tsp_intr_off &nt36523_tsp_reset_off &nt36523_tsp_off_cs &nt36523_tsp_off_clk &nt36523_tsp_off_mosi &nt36523_tsp_off_miso>;

		novatek,reset-gpio = <SEC_GPIO_REF(AP,pio,7) 0x00>;
		novatek,irq-gpio = <SEC_GPIO_REF(AP,pio,14) 0x2002>;

		novatek,enable_sysinput_enabled;
	};
};
/* /home/dpi/qb5_8814/workspace/P4_1716/android/kernel/kmodule/input/touchscreen/novatek/nt36523_spi/dts/input-mtk-tsp-nt36523-spi.a13x.dtsi */
&pio {
	nt36523_tsp_id1_default: nt36523_tsp_id1_default {
		pins_cmd_dat {
			pinmux = <PINMUX_GPIO172__FUNC_GPIO172>;
			slew-rate = <0>;
			input-enable;
			bias-disable;
		};
	};

	nt36523_tsp_id2_default: nt36523_tsp_id2_default {
		pins_cmd_dat {
			pinmux = <PINMUX_GPIO173__FUNC_GPIO173>;
			slew-rate = <0>;
			input-enable;
			bias-disable;
		};
	};

	nt36523_tsp_id3_default: nt36523_tsp_id3_default {
		pins_cmd_dat {
			pinmux = <PINMUX_GPIO174__FUNC_GPIO174>;
			slew-rate = <0>;
			input-enable;
			bias-disable;
		};
	};
};

&spi1 {
	num-cs = <3>;
};

&tsp_novatek{
	pinctrl-names = "default", "on_state", "off_state";
	pinctrl-0 = <&nt36523_tsp_intr_on &nt36523_tsp_reset_on &nt36523_tsp_on_cs &nt36523_tsp_on_clk &nt36523_tsp_on_mosi &nt36523_tsp_on_miso &nt36523_tsp_id1_default &nt36523_tsp_id2_default &nt36523_tsp_id3_default>;
	pinctrl-1 = <&nt36523_tsp_intr_on &nt36523_tsp_reset_on &nt36523_tsp_on_cs &nt36523_tsp_on_clk &nt36523_tsp_on_mosi &nt36523_tsp_on_miso &nt36523_tsp_id1_default &nt36523_tsp_id2_default &nt36523_tsp_id3_default>;
	pinctrl-2 = <&nt36523_tsp_intr_off &nt36523_tsp_reset_off &nt36523_tsp_off_cs &nt36523_tsp_off_clk &nt36523_tsp_off_mosi &nt36523_tsp_off_miso &nt36523_tsp_id1_default &nt36523_tsp_id2_default &nt36523_tsp_id3_default>;

	novatek,resolution = <720 1600>;
	novatek,enable_settings_aot;
	novatek,support_ear_detect_mode;
	novatek,prox_lp_scan_enabled;

	novatek,lcdid1-gpio = <&pio 172 0x0>;
	novatek,lcdid2-gpio = <&pio 173 0x0>;
	novatek,lcdid3-gpio = <&pio 174 0x0>;
	novatek,lcdid = <3 6>;	// 0,0,0,BOE,0,0,sharp
	novatek,lcdtype = <0 0 0 0x2a6244 0 0 0x2af244>;
	novatek,fw_name = "","","","tsp_novatek/nt36525c_a13x_boe.bin","","","tsp_novatek/nt36525c_a13x_sharp.bin";
	novatek,fw_name_mp = "","","","tsp_novatek/nt36525c_a13x_mp_boe.bin","","","tsp_novatek/nt36525c_a13x_mp_sharp.bin";

	novatek,name_lcd_vddi = "vcamio";
	novatek,name_lcd_rst = "gpio_lcd_rst";
	novatek,name_lcd_bl_en = "gpio_lcd_bl_en";

	/* 672A, 525B, 675, 526, 672C */
	novatek,swrst-n8-addr = <0x03F0FE>;
	novatek,spi-rd-fast-addr = <0x03F310>;
	/* MP */
	novatek,mp-support-dt;
	/* nt36525_a12_ltps */
//	novatek-mp-criteria-722A@3 {
//		#address-cells = <1>;
//		#size-cells = <0>;
//		compatible = "novatek-mp-criteria-722A";
		/* sec cmd test config */
//		open_test_spec = <(-511) 5120>;
//		short_test_spec = <10000 14008>;
//		diff_test_frame = <50>;
		/* sec cmd fdm test config */
//		fdm_x_num = <2>;
//		fdm_diff_test_frame = <50>;
//	};
};

/* #include "../input_td4150_spi.dtsi" */            /* From input_td4150_spi.py */
/* NEED TO FIX IF YOU WANT USE THIS */


&pio {
	ovt_tsp_int_on: ovt_tsp_int_on {
		pins_cmd_dat {
			pinmux = <MTK_PINMUX(SEC_GPIO_NUM(AP,pio,14), 0)>;
			slew-rate = <0>;
			bias-disable;
		};
	};

	ovt_tsp_int_off: ovt_tsp_int_off {
		pins_cmd_dat {
			pinmux = <MTK_PINMUX(SEC_GPIO_NUM(AP,pio,14), 0)>;
			slew-rate = <0>;
			input-enable;
			bias-pull-down;
		};
	};
};
&pio {
	ovt_tsp_reset_on: ovt_tsp_reset_on {
		pins_cmd_dat{
			pinmux = <MTK_PINMUX(SEC_GPIO_NUM(AP,pio,7), 0)>;
			slew-rate = <1>;
			bias-disable;
			output-high;
		};
	};

	ovt_tsp_reset_off: ovt_tsp_reset_off {
		pins_cmd_dat{
			pinmux = <MTK_PINMUX(SEC_GPIO_NUM(AP,pio,7), 0)>;
			slew-rate = <1>;
			bias-disable;
			output-low;
		};
	};
};
&pio {
	ovt_tsp_on_cs: ovt_tsp_on_cs {
		pins_cmd_dat{
			pinmux = <MTK_PINMUX(SEC_GPIO_NUM(AP,pio,28), 1)>;
			bias-disable;
		};
	};
	ovt_tsp_off_cs: ovt_tsp_off_cs {
		pins_cmd_dat{
			pinmux = <MTK_PINMUX(SEC_GPIO_NUM(AP,pio,28), 0)>;
			slew-rate = <1>;
			bias-disable;
			output-low;
		};
	};
};
&pio {
	ovt_tsp_on_clk: ovt_tsp_on_clk {
		pins_cmd_dat{
			pinmux = <MTK_PINMUX(SEC_GPIO_NUM(AP,pio,27), 1)>;
			bias-disable;
		};
	};
	ovt_tsp_off_clk: ovt_tsp_off_clk {
		pins_cmd_dat{
			pinmux = <MTK_PINMUX(SEC_GPIO_NUM(AP,pio,27), 0)>;
			slew-rate = <1>;
			bias-disable;
			output-low;
		};
	};

	ovt_tsp_on_mosi: ovt_tsp_on_mosi {
		pins_cmd_dat{
			pinmux = <MTK_PINMUX(SEC_GPIO_NUM(AP,pio,29), 1)>;
			bias-disable;
		};
	};
	ovt_tsp_off_mosi: ovt_tsp_off_mosi {
		pins_cmd_dat{
			pinmux = <MTK_PINMUX(SEC_GPIO_NUM(AP,pio,29), 0)>;
			slew-rate = <1>;
			bias-disable;
			output-low;
		};
	};

	ovt_tsp_on_miso: ovt_tsp_on_miso {
		pins_cmd_dat{
			pinmux = <MTK_PINMUX(SEC_GPIO_NUM(AP,pio,30), 1)>;
			bias-disable;
		};
	};

	ovt_tsp_off_miso: ovt_tsp_off_miso {
		pins_cmd_dat{
			pinmux = <MTK_PINMUX(SEC_GPIO_NUM(AP,pio,30), 0)>;
			slew-rate = <0>;
			bias-pull-down;
			input-enable;
		};
	};
};

&spi1 {
	status = "okay";
	#address-cells = <1>;
	#size-cells = <0>;
	num-cs = <1>;

	tsp_ovt: ovt_tcm@1 {
		status = "okay";
		compatible = "ovt,tcm-spi";
		reg = <1>;
		spi-max-frequency = <7000000>;

		pinctrl-names = "default", "on_state", "off_state";
		pinctrl-0 = <&ovt_tsp_int_on &ovt_tsp_reset_on &ovt_tsp_on_miso &ovt_tsp_on_cs &ovt_tsp_on_mosi &ovt_tsp_on_clk>;
		pinctrl-1 = <&ovt_tsp_int_on &ovt_tsp_reset_on &ovt_tsp_on_miso &ovt_tsp_on_cs &ovt_tsp_on_mosi &ovt_tsp_on_clk>;
		pinctrl-2 = <&ovt_tsp_int_off &ovt_tsp_reset_off &ovt_tsp_off_miso &ovt_tsp_off_cs &ovt_tsp_off_mosi &ovt_tsp_off_clk>;

		ovt,irq-gpio = <SEC_GPIO_REF(AP,pio,14) 0x2008>; /* IRQF_ONESHOT | IRQF_TRIGGER_LOW */
		ovt,cs-gpio = <SEC_GPIO_REF(AP,pio,28) 0x00>;
		ovt,irq-on-state = <0>;
		ovt,spi-mode = <3>;
		ovt,byte-delay-us = <0>;
		ovt,block-delay-us = <0>;
		ovt,ubl-max-freq = <7000000>;
		ovt,ubl-byte-delay-us = <20>;

		ovt,enable_sysinput_enabled;
	};
};


/* /home/dpi/qb5_8814/workspace/P4_1716/android/kernel/kmodule/input/touchscreen/ovt/td4150_spi/dts/input-mtk-tsp-td4150_spi.a13x.dtsi */
&pio {
	ovt_tsp_id1_default: ovt_tsp_id1_default {
		pins_cmd_dat {
			pinmux = <PINMUX_GPIO172__FUNC_GPIO172>;
			slew-rate = <0>;
			input-enable;
			bias-disable;
		};
	};

	ovt_tsp_id2_default: ovt_tsp_id2_default {
		pins_cmd_dat {
			pinmux = <PINMUX_GPIO173__FUNC_GPIO173>;
			slew-rate = <0>;
			input-enable;
			bias-disable;
		};
	};

	ovt_tsp_id3_default: ovt_tsp_id3_default {
		pins_cmd_dat {
			pinmux = <PINMUX_GPIO174__FUNC_GPIO174>;
			slew-rate = <0>;
			input-enable;
			bias-disable;
		};
	};
};

/* touch gpio end */

&spi1 {
	num-cs = <3>;
};

&tsp_ovt {
	pinctrl-names = "default", "on_state", "off_state";
	pinctrl-0 = <&ovt_tsp_int_on &ovt_tsp_reset_on &ovt_tsp_on_miso &ovt_tsp_on_cs &ovt_tsp_on_mosi &ovt_tsp_on_clk &ovt_tsp_id1_default &ovt_tsp_id2_default &ovt_tsp_id3_default>;
	pinctrl-1 = <&ovt_tsp_int_on &ovt_tsp_reset_on &ovt_tsp_on_miso &ovt_tsp_on_cs &ovt_tsp_on_mosi &ovt_tsp_on_clk &ovt_tsp_id1_default &ovt_tsp_id2_default &ovt_tsp_id3_default>;
	pinctrl-2 = <&ovt_tsp_int_off &ovt_tsp_reset_off &ovt_tsp_off_miso &ovt_tsp_off_cs &ovt_tsp_off_mosi &ovt_tsp_off_clk &ovt_tsp_id1_default &ovt_tsp_id2_default &ovt_tsp_id3_default>;

	ovt,area-size = <48 81 30>;
	ovt,regulator_lcd_vdd = "vcamio";
	ovt,regulator_lcd_bl = "gpio_lcd_bl_en";
	ovt,regulator_lcd_reset = "gpio_lcd_rst";
	ovt,lcdid1-gpio = <&pio 172 0x0>;
	ovt,lcdid2-gpio = <&pio 173 0x0>;
	ovt,lcdid3-gpio = <&pio 174 0x0>;
	ovt,enable_settings_aot;
	ovt,support_ear_detect_mode;
	ovt,support_spay_gesture_mode;
	ovt,support_cs_gpio_control;
	ovt,prox_lp_scan_enabled;
	ovt,lcdid = <0>;	// BOE-TD4375, BOE-TD4150, BOE-TD4160
	ovt,lcdtype = <0x2A6220>;
	ovt,fw_name = "tsp_ovt/td4160_a13x_boe.bin";
};


/* #include "../sec_thermistor-3.dtsi" */            /* From sec_thermistor.py */
/ {
	fragment@smd {
		target-path = "/";
		__overlay__ {
			samsung_mobile_device {
				sec_wf_thermistor: sec_thermistor@3 {
					compatible = "samsung,sec-thermistor";
					status = "okay";
					thermistor_name = "sec-wf-thermistor";
					id = <3>;

					io-channels = SEC_ADC(auxadc,4);
					io-channel-names = "wf_therm";
					io-channel-ranges;
				};
			};
		};
	};
};

/* #include "../sec_thermistor-2.dtsi" */            /* From sec_thermistor.py */
/ {
	fragment@smd {
		target-path = "/";
		__overlay__ {
			samsung_mobile_device {
				sec_cp_thermistor: sec_thermistor@2 {
					compatible = "samsung,sec-thermistor";
					status = "okay";
					thermistor_name = "sec-cp-thermistor";
					id = <2>;

					io-channels = SEC_ADC(auxadc,2);
					io-channel-names = "cp_therm";
					io-channel-ranges;
				};
			};
		};
	};
};

/* #include "../sec_thermistor-1.dtsi" */            /* From sec_thermistor.py */
/ {
	fragment@smd {
		target-path = "/";
		__overlay__ {
			samsung_mobile_device {
				sec_pa_thermistor: sec_thermistor@1 {
					compatible = "samsung,sec-thermistor";
					status = "okay";
					thermistor_name = "sec-pa-thermistor";
					id = <1>;

					io-channels = SEC_ADC(auxadc,1);
					io-channel-names = "pa_therm";
					io-channel-ranges;
				};
			};
		};
	};
};

/* #include "../sec_thermistor.dtsi" */              /* From sec_thermistor.py */
/ {
	fragment@smd {
		target-path = "/";
		__overlay__ {
			samsung_mobile_device {
				sec_ap_thermistor: sec_thermistor@0 {
					compatible = "samsung,sec-thermistor";
					status = "okay";
					thermistor_name = "sec-ap-thermistor";
					id = <0>;

					io-channels = SEC_ADC(auxadc,0);
					io-channel-names = "ap_therm";
					io-channel-ranges;
				};
			};
		};
	};
};

/* /home/dpi/qb5_8814/workspace/P4_1716/android/kernel/kmodule/hwmon/sec_thermistor/sec_thermistor_mtk.a13x.dtsi */
&sec_ap_thermistor {
	use_iio_processed;
	adc_array = <108 124 177 209 254 308 373 442 525 590
				652 758 855 912 1092 1318 1556 1824 1929 2130
				2323 2458 2795 3088 3320>;

	temp_array = <850 800 700 650 600 550 500 450 400 370
				350 300 270 250 200 150 100 50 30 0
				(-30) (-50) (-100) (-150) (-200)>;
};

&sec_pa_thermistor {
	use_iio_processed;
	adc_array = <394 475 652 758 896 1050 1226 1402 1600 1744
				1874 2089 2260 2356 2633 2934 3202 3461 3558 3712
				3853 3940>;

	temp_array = <850 800 700 650 600 550 500 450 400 370
				350 300 270 250 200 150 100 50 30 0
				(-30) (-50)>;
};

&sec_cp_thermistor {
	use_iio_processed;
	adc_array = <382 475 652 757 895 1049 1224 1402 1595 1741
				1868 2084 2255 2352 2629 2930 3199 3456 3550 3710
				3849 3939>;

	temp_array = <850 800 700 650 600 550 500 450 400 370
				350 300 270 250 200 150 100 50 30 0
				(-30) (-50)>;
};

&sec_wf_thermistor {
	use_iio_processed;
	adc_array = <393 475 650 758 885 1050 1226 1399 1597 1740
				1865 2074 2239 2341 2619 2885 3186 3446 3558 3703
				3837 3936>;

	temp_array = <850 800 700 650 600 550 500 450 400 370
				350 300 270 250 200 150 100 50 30 0
				(-30) (-50)>;
};
/* #include "../pmic_MT6360.dtsi" */                 /* From pmic_MT6360.py */
#if 1800000 && 1800000
&mt_pmic_vfp_ldo_reg {
    regulator-min-microvolt = <1800000>;
    regulator-max-microvolt = <1800000>;
     
     
};
#endif

#if 1800000 && 1800000
&mt_pmic_vtp_ldo_reg {
    regulator-min-microvolt = <1800000>;
    regulator-max-microvolt = <1800000>;
     regulator-always-on;
     
};
#endif

#if 0 && 0
&mt_pmic_vmc_ldo_reg {
    regulator-min-microvolt = <0>;
    regulator-max-microvolt = <0>;
     
     
};
#endif

#if 0 && 0
&mt_pmic_vmch_ldo_reg {
    regulator-min-microvolt = <0>;
    regulator-max-microvolt = <0>;
     
     
};
#endif

#if 0 && 0
&mt_pmic_vdram2_ldo_reg {
    regulator-min-microvolt = <${mt_pmic_vdram2_ldo7_ldo_reg_Vmin}>;
    regulator-max-microvolt = <${mt_pmic_vdram2_ldo7_ldo_reg_Vmax}>;
    ${mt_pmic_vdram2_ldo7_ldo_reg_basic_properties}
    ${mt_pmic_vdram2_ldo7_ldo_reg_opt_properties}
};
#endif
/* #include "../pmic_MT6365.dtsi" */                 /* From pmic_MT6365.py */
#if 0 && 0
&mt_pmic_vaud18_ldo_reg {
    regulator-min-microvolt = <0>;
    regulator-max-microvolt = <0>;
     
     
};
#endif

#if 0 && 0
&mt_pmic_vsim1_ldo_reg {
    regulator-min-microvolt = <0>;
    regulator-max-microvolt = <0>;
     
     
};
#endif

#if 3300000 && 3300000
&mt_pmic_vibr_ldo_reg {
    regulator-min-microvolt = <3300000>;
    regulator-max-microvolt = <3300000>;
     
     
};
#endif

#if 0 && 0
&mt_pmic_vrf12_ldo_reg {
    regulator-min-microvolt = <0>;
    regulator-max-microvolt = <0>;
     
     
};
#endif

#if 0 && 0
&mt_pmic_vusb_ldo_reg {
    regulator-min-microvolt = <0>;
    regulator-max-microvolt = <0>;
     
     
};
#endif

#if 0 && 0
&mt_pmic_vsram_proc2_ldo_reg {
    regulator-min-microvolt = <0>;
    regulator-max-microvolt = <0>;
     
     
};
#endif

#if 0 && 0
&mt_pmic_vio18_ldo_reg {
    regulator-min-microvolt = <0>;
    regulator-max-microvolt = <0>;
     
     
};
#endif

#if 0 && 0
&mt_pmic_vcamio_ldo_reg {
    regulator-min-microvolt = <0>;
    regulator-max-microvolt = <0>;
     
     
};
#endif

#if 0 && 0
&mt_pmic_vcn18_ldo_reg {
    regulator-min-microvolt = <0>;
    regulator-max-microvolt = <0>;
     
     
};
#endif

#if 0 && 0
&mt_pmic_vfe28_ldo_reg {
    regulator-min-microvolt = <0>;
    regulator-max-microvolt = <0>;
     
     
};
#endif

#if 0 && 0
&mt_pmic_vcn13_ldo_reg {
    regulator-min-microvolt = <0>;
    regulator-max-microvolt = <0>;
     
     
};
#endif

#if 0 && 0
&mt_pmic_vcn33_1_bt_ldo_reg {
    regulator-min-microvolt = <0>;
    regulator-max-microvolt = <0>;
     
     
};
#endif

#if 0 && 0
&mt_pmic_vcn33_1_wifi_ldo_reg {
    regulator-min-microvolt = <0>;
    regulator-max-microvolt = <0>;
     
     
};
#endif

#if 0 && 0
&mt_pmic_vaux18_ldo_reg {
    regulator-min-microvolt = <0>;
    regulator-max-microvolt = <0>;
     
     
};
#endif

#if 0 && 0
&mt_pmic_vsram_others_ldo_reg {
    regulator-min-microvolt = <0>;
    regulator-max-microvolt = <0>;
     
     
};
#endif

#if 0 && 0
&mt_pmic_vefuse_ldo_reg {
    regulator-min-microvolt = <0>;
    regulator-max-microvolt = <0>;
     
     
};
#endif

#if 0 && 0
&mt_pmic_vxo22_ldo_reg {
    regulator-min-microvolt = <0>;
    regulator-max-microvolt = <0>;
     
     
};
#endif

#if 0 && 0
&mt_pmic_vrfck_ldo_reg {
    regulator-min-microvolt = <0>;
    regulator-max-microvolt = <0>;
     
     
};
#endif

#if 0 && 0
&mt_pmic_vbif28_ldo_reg {
    regulator-min-microvolt = <0>;
    regulator-max-microvolt = <0>;
     
     
};
#endif

#if 0 && 0
&mt_pmic_vio28_ldo_reg {
    regulator-min-microvolt = <0>;
    regulator-max-microvolt = <0>;
     
     
};
#endif

#if 0 && 0
&mt_pmic_vemc_ldo_reg {
    regulator-min-microvolt = <0>;
    regulator-max-microvolt = <0>;
     
     
};
#endif

#if 0 && 0
&mt_pmic_vcn33_2_bt_ldo_reg {
    regulator-min-microvolt = <0>;
    regulator-max-microvolt = <0>;
     
     
};
#endif

#if 0 && 0
&mt_pmic_vcn33_2_wifi_ldo_reg {
    regulator-min-microvolt = <0>;
    regulator-max-microvolt = <0>;
     
     
};
#endif

#if 0 && 0
&mt_pmic_va12_ldo_reg {
    regulator-min-microvolt = <0>;
    regulator-max-microvolt = <0>;
     
     
};
#endif

#if 0 && 0
&mt_pmic_va09_ldo_reg {
    regulator-min-microvolt = <0>;
    regulator-max-microvolt = <0>;
     
     
};
#endif

#if 0 && 0
&mt_pmic_vrf18_ldo_reg {
    regulator-min-microvolt = <0>;
    regulator-max-microvolt = <0>;
     
     
};
#endif

#if 0 && 0
&mt_pmic_vsram_md_ldo_reg {
    regulator-min-microvolt = <0>;
    regulator-max-microvolt = <0>;
     
     
};
#endif

#if 0 && 0
&mt_pmic_vufs_ldo_reg {
    regulator-min-microvolt = <0>;
    regulator-max-microvolt = <0>;
     
     
};
#endif

#if 0 && 0
&mt_pmic_vm18_ldo_reg {
    regulator-min-microvolt = <0>;
    regulator-max-microvolt = <0>;
     
     
};
#endif

#if 0 && 0
&mt_pmic_vbbck_ldo_reg {
    regulator-min-microvolt = <0>;
    regulator-max-microvolt = <0>;
     
     
};
#endif

#if 0 && 0
&mt_pmic_vsram_proc1_ldo_reg {
    regulator-min-microvolt = <0>;
    regulator-max-microvolt = <0>;
     
     
};
#endif

#if 0 && 0
&mt_pmic_vsim2_ldo_reg {
    regulator-min-microvolt = <0>;
    regulator-max-microvolt = <0>;
     
     
};
#endif

/* #include "../input_hx83xxx_spi.dtsi" */           /* From input_hx83xxx_spi.py */
/* NEED TO FIX IF YOU WANT USE THIS */

&pio {
	himax_tsp_intr_on: himax_tsp_intr_on {
		pins_cmd_dat {
			pinmux = <MTK_PINMUX(SEC_GPIO_NUM(AP,pio,14), 0)>;
			slew-rate = <0>;
			bias-disable;
		};
	};

	himax_tsp_intr_off: himax_tsp_intr_off {
		pins_cmd_dat {
			pinmux = <MTK_PINMUX(SEC_GPIO_NUM(AP,pio,14), 0)>;
			slew-rate = <0>;
			input-enable;
			bias-pull-down;
		};
	};
};
&pio {
	himax_tsp_reset_on: himax_tsp_reset_on {
		pins_cmd_dat{
			pinmux = <MTK_PINMUX(SEC_GPIO_NUM(AP,pio,7), 0)>;
			slew-rate = <1>;
			bias-disable;
			output-high;
		};
	};

	himax_tsp_reset_off: himax_tsp_reset_off {
		pins_cmd_dat{
			pinmux = <MTK_PINMUX(SEC_GPIO_NUM(AP,pio,7), 0)>;
			slew-rate = <1>;
			bias-disable;
			output-low;
		};
	};
};
&pio {
	himax_tsp_on_cs: himax_tsp_on_cs {
		pins_cmd_dat{
			pinmux = <MTK_PINMUX(SEC_GPIO_NUM(AP,pio,28), 1)>;
			bias-disable;
		};
	};
	himax_tsp_off_cs: himax_tsp_off_cs {
		pins_cmd_dat{
			pinmux = <MTK_PINMUX(SEC_GPIO_NUM(AP,pio,28), 0)>;
			slew-rate = <1>;
			bias-disable;
			output-low;
		};
	};
};
&pio {
	himax_tsp_on_clk: himax_tsp_on_clk {
		pins_cmd_dat{
			pinmux = <MTK_PINMUX(SEC_GPIO_NUM(AP,pio,27), 1)>;
			bias-disable;
		};
	};
	himax_tsp_off_clk: himax_tsp_off_clk {
		pins_cmd_dat{
			pinmux = <MTK_PINMUX(SEC_GPIO_NUM(AP,pio,27), 0)>;
			slew-rate = <1>;
			bias-disable;
			output-low;
		};
	};

	himax_tsp_on_mosi: himax_tsp_on_mosi {
		pins_cmd_dat{
			pinmux = <MTK_PINMUX(SEC_GPIO_NUM(AP,pio,29), 1)>;
			bias-disable;
		};
	};
	himax_tsp_off_mosi: himax_tsp_off_mosi {
		pins_cmd_dat{
			pinmux = <MTK_PINMUX(SEC_GPIO_NUM(AP,pio,29), 0)>;
			slew-rate = <1>;
			bias-disable;
			output-low;
		};
	};

	himax_tsp_on_miso: himax_tsp_on_miso {
		pins_cmd_dat{
			pinmux = <MTK_PINMUX(SEC_GPIO_NUM(AP,pio,30), 1)>;
			bias-disable;
		};
	};

	himax_tsp_off_miso: himax_tsp_off_miso {
		pins_cmd_dat{
			pinmux = <MTK_PINMUX(SEC_GPIO_NUM(AP,pio,30), 0)>;
			slew-rate = <0>;
			bias-pull-down;
			input-enable;
		};
	};

	himax_default_miso: himax_default_miso {
		pins_cmd_dat{
			pinmux = <MTK_PINMUX(SEC_GPIO_NUM(AP,pio,30), 0)>;
			slew-rate = <0>;
			bias-disable;
			output-low;
		};
	};
};

&spi1 {
	status = "okay";
	#address-cells = <1>;
	#size-cells = <0>;
	num-cs = <1>;
	tsp_himax: himax_ts@0 {
		compatible = "himax,hxcommon";

		pinctrl-names = "default", "on_state", "off_state";
		pinctrl-0 = <&himax_tsp_intr_on &himax_tsp_reset_on &himax_tsp_on_miso &himax_tsp_on_cs &himax_tsp_on_mosi &himax_tsp_on_clk>;
		pinctrl-1 = <&himax_tsp_intr_on &himax_tsp_reset_on &himax_tsp_on_miso &himax_tsp_on_cs &himax_tsp_on_mosi &himax_tsp_on_clk>;
		pinctrl-2 = <&himax_tsp_intr_off &himax_tsp_off_miso &himax_tsp_off_cs &himax_tsp_off_mosi &himax_tsp_off_clk>;
		//&reset_off need to control at driver, spi low -> need 1frame delay -> tsp_reset low.

		reg = <0>; //Same as CS ID
		spi-max-frequency = <10000000>;
		himax,rst-gpio = <SEC_GPIO_REF(AP,pio,7) 0x00>;
		himax,irq-gpio = <SEC_GPIO_REF(AP,pio,14) 0x00>;

		himax,enable_sysinput_enabled;
	};
};

/* /home/dpi/qb5_8814/workspace/P4_1716/android/kernel/kmodule/input/touchscreen/himax/hx83xxx_spi/dts/input-mtk-tsp-hx83xxx_spi.a13x.dtsi */
&pio {
	himax_tsp_id1_default: himax_tsp_id1_default {
		pins_cmd_dat {
			pinmux = <PINMUX_GPIO172__FUNC_GPIO172>;
			slew-rate = <0>;
			input-enable;
			bias-disable;
		};
	};

	himax_tsp_id2_default: himax_tsp_id2_default {
		pins_cmd_dat {
			pinmux = <PINMUX_GPIO173__FUNC_GPIO173>;
			slew-rate = <0>;
			input-enable;
			bias-disable;
		};
	};

	himax_tsp_id3_default: himax_tsp_id3_default {
		pins_cmd_dat {
			pinmux = <PINMUX_GPIO174__FUNC_GPIO174>;
			slew-rate = <0>;
			input-enable;
			bias-disable;
		};
	};
};

&spi1 {
	num-cs = <3>;
};
&tsp_himax{
	pinctrl-names = "default", "on_state", "off_state";
	pinctrl-0 = <&himax_tsp_intr_on &himax_tsp_reset_on &himax_tsp_on_miso &himax_tsp_on_cs &himax_tsp_on_mosi &himax_tsp_on_clk &himax_tsp_id1_default &himax_tsp_id2_default &himax_tsp_id3_default>;
	pinctrl-1 = <&himax_tsp_intr_on &himax_tsp_reset_on &himax_tsp_on_miso &himax_tsp_on_cs &himax_tsp_on_mosi &himax_tsp_on_clk &himax_tsp_id1_default &himax_tsp_id2_default &himax_tsp_id3_default>;
	pinctrl-2 = <&himax_tsp_intr_off &himax_tsp_off_miso &himax_tsp_off_cs &himax_tsp_off_mosi &himax_tsp_off_clk &himax_tsp_id1_default &himax_tsp_id2_default &himax_tsp_id3_default>;
	//&reset_off need to control at driver, spi low -> need 1frame delay -> tsp_reset low.

	himax,panel-coords = <720 1600>;
	himax,display-coords = <720 1600>;
	himax,notch-setting = <287 319>;
	himax,fix_touch_info = <32 18 0 720 1600 10 1 1>;
	//FIX_HX_RX_NUM,FIX_HX_TX_NUM,FIX_HX_BT_NUM,FIX_HX_X_RES,FIX_HX_Y_RES,FIX_HX_MAX_PT,FIX_HX_XY_REVERSE
	himax,project_name = "A13X", "A136";

	support_aot;
	himax,support_ear_detect_mode;
	himax,support_spay_gesture_mode;
	himax,prox_lp_scan_enabled;

	himax,lcdid1-gpio = <&pio 172 0x0>;
	himax,lcdid2-gpio = <&pio 173 0x0>;
	himax,lcdid3-gpio = <&pio 174 0x0>;
	himax,lcdid = <5>;	// 0,0,0,0,0,BOE_Himax
	himax,lcdtype = <0 0 0 0 0 0x2a6234>;
	himax,fw_name = "","","","","","tsp_himax/hx83108a_a13x.bin";

	himax,name_lcd_vddi = "vcamio";
	himax,name_lcd_rst = "gpio_lcd_rst";
	himax,name_lcd_bl_en = "gpio_lcd_bl_en";
	himax,one_frame_delay = <20>;
	himax,report_type = <1>;
};

/* #include "../sensors_a96t396.dtsi" */             /* From sensors_a96t396.py */
#if 1

&pio {
	grip_i2c_sda: grip-i2c-sda {
		GPIO_CONFIG_PUD_DRV(AP,pio,112, FUNC_INPUT, PULL_UP, DRV_LV1);
	};
	grip_i2c_scl: grip-i2c-scl {
		GPIO_CONFIG_PUD_DRV(AP,pio,111, FUNC_INPUT, PULL_UP, DRV_LV1);
	};
};

&pio {
	grip_int: grip-int {
		GPIO_CONFIG_PUD_DRV(AP,pio,17, FUNC_INPUT_WAKEUP, PULL_NONE, DRV_LV1);
	};
};

&i2c7 {
	gpios = <SEC_GPIO_REF(AP,pio,112) 0 /* sda */
			SEC_GPIO_REF(AP,pio,111) 0>; /* scl */
	pinctrl-0 = <&grip_i2c_sda
				 &grip_i2c_scl
				 >;
	#address-cells = <1>;
	#size-cells = <0>;
	status = "okay";
	clock-frequency = <100000>;
	a96t396: a96t396@20 {
		compatible = "a96t396";
		reg = <0x20>;

		pinctrl-names = "default";
		pinctrl-0 = <&grip_int>;

		interrupt-parent = <SEC_GPIO_TYPE(AP,pio,17)>;
		interrupts = <SEC_GPIO_NUM(AP,pio,17) 0>;

		a96t396,irq_gpio = <SEC_GPIO_REF(AP,pio,17) 0>;
#if 1
		a96t396,ldo_en = <SEC_GPIO_REF(AP,pio,139) 0>;
#endif
#if 0
		a96t396,dvdd_vreg_name = "VDD_GRIP_3P3";
#endif
		a96t396,multi_use = <1>;
#if 1
		a96t396,unknown_ch_selection = <3>; /*bit "0 0" => no use , "0 1" => 1ch only, "1 0" => 2ch only, "1 1" 1ch 2ch both*/
#endif
		a96t396,fw_path = "abov/a96t396_a13x_eur_main.bin";
		a96t396,firmup_cmd = <0x90>;
	};
};
#endif

/* ---- SUB GRIP---- */
#if 1

&pio {
	grip_sub_i2c_sda: grip-sub-i2c-sda {
		GPIO_CONFIG_PUD_DRV(AP,pio,112, FUNC_INPUT, PULL_UP, DRV_LV1);
	};
	grip_sub_i2c_scl: grip-sub-i2c-scl {
		GPIO_CONFIG_PUD_DRV(AP,pio,111, FUNC_INPUT, PULL_UP, DRV_LV1);
	};
};

&pio {
	grip_sub_int: grip-sub-int {
		GPIO_CONFIG_PUD_DRV(AP,pio,18, FUNC_INPUT_WAKEUP, PULL_NONE, DRV_LV1);
	};
};

&i2c7 {
	gpios = <SEC_GPIO_REF(AP,pio,112) 0 /* sda */
			SEC_GPIO_REF(AP,pio,111) 0>; /* scl */
	pinctrl-0 = <&grip_sub_i2c_sda
				 &grip_sub_i2c_scl
				>;
	#address-cells = <1>;
	#size-cells = <0>;
	status = "okay";
	clock-frequency = <100000>;
	a96t396_sub: a96t396_sub@21 {

		compatible = "a96t396_sub";
		reg = <0x21>;

		pinctrl-names = "default";
		pinctrl-0 = <&grip_sub_int>;

		interrupt-parent = <SEC_GPIO_TYPE(AP,pio,18)>;
		interrupts = <SEC_GPIO_NUM(AP,pio,18) 0>;

		a96t396_sub,irq_gpio = <SEC_GPIO_REF(AP,pio,18) 0>;
#if 0
		a96t396_sub,ldo_en = <SEC_GPIO_REF(${gpio_grip_sub_ldo_en}) 0>;
#else
		a96t396_sub,ldo_en = <SEC_GPIO_REF(AP,pio,139) 0>;
#endif
#if 0
		a96t396_sub,dvdd_vreg_name = "VDD_GRIP_3P3";
#endif
		a96t396_sub,multi_use = <0>;
#if 1
		a96t396_sub,unknown_ch_selection = <3>; /*bit "0 0" => no use , "0 1" => 1ch only, "1 0" => 2ch only, "1 1" 1ch 2ch both*/
#endif
		a96t396_sub,fw_path = "abov/a96t396_a13x_eur_sub.bin";
		a96t396_sub,firmup_cmd = <0x90>;
	};
};
#endif

/* ---- WIFI GRIP---- */
#if 0

&${gpio_grip_wifi_i2c_parent} {
	grip_wifi_i2c_sda: grip-wifi-i2c-sda {
		GPIO_CONFIG_PUD_DRV(${gpio_grip_wifi_i2c_sda}, FUNC_INPUT, PULL_UP, DRV_LV1);
	};
	grip_wifi_i2c_scl: grip-wifi-i2c-scl {
		GPIO_CONFIG_PUD_DRV(${gpio_grip_wifi_i2c_scl}, FUNC_INPUT, PULL_UP, DRV_LV1);
	};
};

&${gpio_grip_wifi_irq_parent} {
	grip_wifi_int: grip-wifi-int {
		GPIO_CONFIG_PUD_DRV(${gpio_grip_wifi_irq}, FUNC_INPUT_WAKEUP, PULL_NONE, DRV_LV1);
	};
};

&${i2c_grip_wifi} {
	gpios = <SEC_GPIO_REF(${gpio_grip_wifi_i2c_sda}) 0 /* sda */
			SEC_GPIO_REF(${gpio_grip_wifi_i2c_scl}) 0>; /* scl */
	pinctrl-0 = <&grip_wifi_i2c_sda
				 &grip_wifi_i2c_scl
				>;
	#address-cells = <1>;
	#size-cells = <0>;
	status = "okay";
	clock-frequency = <100000>;
	a96t396_wifi: a96t396_wifi@${a96t396_wifi_address} {

		compatible = "a96t396_wifi";
		reg = <0x${a96t396_wifi_address}>;

		pinctrl-names = "default";
		pinctrl-0 = <&grip_wifi_int>;

		interrupt-parent = <SEC_GPIO_TYPE(${gpio_grip_wifi_irq})>;
		interrupts = <SEC_GPIO_NUM(${gpio_grip_wifi_irq}) 0>;

		a96t396_wifi,irq_gpio = <SEC_GPIO_REF(${gpio_grip_wifi_irq}) 0>;
#if 0
		a96t396_wifi,ldo_en = <SEC_GPIO_REF(${gpio_grip_wifi_ldo_en}) 0>;
#else
		a96t396_wifi,ldo_en = <SEC_GPIO_REF(AP,pio,139) 0>;
#endif
#if 0
		a96t396_wifi,dvdd_vreg_name = "VDD_GRIP_3P3";
#endif
		a96t396_wifi,multi_use = <0>;
#if 0
		a96t396_wifi,unknown_ch_selection = <${a96t396_wifi_unknown_ch_sel}>; /*bit "0 0" => no use , "0 1" => 1ch only, "1 0" => 2ch only, "1 1" 1ch 2ch both*/
#endif
		a96t396_wifi,fw_path = "abov/a96t396_a13x_eur_wifi.bin";
		a96t396_wifi,firmup_cmd = <0x90>;
	};
};
#endif
/* /home/dpi/qb5_8814/workspace/P4_1716/android/kernel/kmodule/sensors/a96t396/dts/a96t396.a13x.dtsi */
&grip_i2c_sda {
	GPIO_CONFIG_PUD_DRV(AP,pio,112, FUNC_INPUT, PULL_UP, DRV_LV1);
};

&grip_i2c_scl {
	GPIO_CONFIG_PUD_DRV(AP,pio,111, FUNC_INPUT, PULL_UP, DRV_LV1);
};
/* #include "../battery_common.dtsi" */              /* From battery_common.py */
#include <dt-bindings/battery/sec-battery.h>

&smd {
	sec_battery: battery {
		status = "okay";
		compatible = "samsung,sec-battery";
		battery,vendor = "Battery";
		battery,charger_name = "mtk-charger";
		battery,technology = <2>; /* POWER_SUPPLY_TECHNOLOGY_LION */

		battery,batt_data_version = <1>;

		battery,temp_adc_type = <SEC_BATTERY_ADC_TYPE_AP>; /* SEC_BATTERY_ADC_TYPE_AP */
		battery,adc_check_count = <5>;
		battery,temp_check_type = <SEC_BATTERY_TEMP_CHECK_NONE>;
		battery,usb_temp_check_type = <SEC_BATTERY_TEMP_CHECK_NONE>;
		battery,chg_temp_check_type = <SEC_BATTERY_TEMP_CHECK_NONE>;
		battery,wpc_temp_check_type = <SEC_BATTERY_TEMP_CHECK_NONE>;

		battery,thermal_source = <SEC_BATTERY_THERMAL_SOURCE_NONE>; /* SEC_BATTERY_THERMAL_SOURCE_NONE */
		battery,usb_thermal_source = <SEC_BATTERY_THERMAL_SOURCE_NONE>; /* SEC_BATTERY_THERMAL_SOURCE_NONE */
		battery,chg_thermal_source = <SEC_BATTERY_THERMAL_SOURCE_NONE>; /* SEC_BATTERY_THERMAL_SOURCE_NONE */
		battery,wpc_thermal_source = <SEC_BATTERY_THERMAL_SOURCE_NONE>; /* SEC_BATTERY_THERMAL_SOURCE_NONE */

		battery,polling_time = <10 30 30 30 3600>;

		battery,cable_check_type = <4>; /* SEC_BATTERY_CABLE_CHECK_PSY */
		battery,cable_source_type = <SEC_BATTERY_CABLE_SOURCE_EXTERNAL>;
		battery,polling_type = <SEC_BATTERY_MONITOR_ALARM>; /* SEC_BATTERY_MONITOR_ALARM */
		battery,monitor_initial_count = <0>;

		battery,battery_check_type = <0>; /* SEC_BATTERY_CHECK_NONE */

		battery,ovp_uvlo_check_type = <SEC_BATTERY_OVP_UVLO_CHGPOLLING>; /* SEC_BATTERY_OVP_UVLO_CHGPOLLING */

		battery,temp_check_count = <1>;
		battery,temp_highlimit_threshold_event = <800>;
		battery,temp_highlimit_recovery_event = <780>;
		battery,temp_high_threshold_event = <500>;
		battery,temp_high_recovery_event = <480>;
		battery,temp_low_threshold_event = <0>;
		battery,temp_low_recovery_event = <20>;
		battery,temp_highlimit_threshold_normal = <800>;
		battery,temp_highlimit_recovery_normal = <780>;
		battery,temp_high_threshold_normal = <500>;
		battery,temp_high_recovery_normal = <480>;
		battery,temp_low_threshold_normal = <0>;
		battery,temp_low_recovery_normal = <20>;
		battery,temp_highlimit_threshold_lpm = <800>;
		battery,temp_highlimit_recovery_lpm = <780>;
		battery,temp_high_threshold_lpm = <500>;
		battery,temp_high_recovery_lpm = <480>;
		battery,temp_low_threshold_lpm = <0>;
		battery,temp_low_recovery_lpm = <20>;
		battery,wpc_high_threshold_normal = <450>;
		battery,wpc_high_recovery_normal = <430>;
		battery,wpc_low_threshold_normal = <0>;
		battery,wpc_low_recovery_normal = <20>;
		battery,full_check_type = <SEC_BATTERY_FULLCHARGED_CHGPSY>;
		battery,full_check_type_2nd = <SEC_BATTERY_FULLCHARGED_CHGPSY>;
		battery,full_check_count = <1>;
		battery,chg_gpio_full_check = <0>;
		battery,chg_polarity_full_check = <1>;

		battery,chg_high_temp = <460>;
		battery,chg_high_temp_recovery = <440>;
		battery,chg_input_limit_current = <1000>;
		battery,chg_charging_limit_current = <1400>;

		battery,wpc_temp_control_source = <TEMP_CONTROL_SOURCE_BAT_THM>;
		battery,wpc_high_temp = <380>;
		battery,wpc_high_temp_recovery = <360>;
		battery,wpc_input_limit_current = <600>;
		battery,wpc_charging_limit_current = <1000>;
		battery,wpc_temp_lcd_on_control_source = <TEMP_CONTROL_SOURCE_BAT_THM>;
		battery,wpc_lcd_on_high_temp = <380>;
		battery,wpc_lcd_on_high_temp_rec = <360>;
		battery,wpc_lcd_on_input_limit_current = <450>;

		battery,wpc_store_high_temp = <360>;
		battery,wpc_store_high_temp_recovery = <340>;
		battery,wpc_store_charging_limit_current = <400>;
		battery,wpc_store_lcd_on_high_temp = <360>;
		battery,wpc_store_lcd_on_high_temp_rec = <300>;
		battery,wpc_store_lcd_on_charging_limit_current = <400>;

		battery,sleep_mode_limit_current = <500>;
		battery,wc_full_input_limit_current = <100>;

		battery,mix_high_temp = <420>;
		battery,mix_high_chg_temp = <500>;
		battery,mix_high_temp_recovery = <390>;

		battery,full_condition_type = <(SEC_BATTERY_FULL_CONDITION_NOTIMEFULL | SEC_BATTERY_FULL_CONDITION_VCELL)>;
		battery,full_condition_soc = <93>;
		battery,full_condition_vcell = <4250>;

		battery,recharge_check_count = <1>;
		battery,recharge_condition_type = <SEC_BATTERY_RECHARGE_CONDITION_VCELL>;
		battery,recharge_condition_soc = <98>;
		battery,recharge_condition_vcell = <4280>;

		battery,charging_total_time = <14400>;
		battery,hv_charging_total_time = <10800>;
		battery,normal_charging_total_time = <18000>;
		battery,usb_charging_total_time = <36000>;
		battery,recharging_total_time = <5400>;
		battery,charging_reset_time = <0>;

		battery,chg_float_voltage = <4350>;

		battery,pre_afc_work_delay = <2000>;
		battery,pre_wc_afc_work_delay = <4000>;
		battery,pre_afc_input_current = <500>;
		battery,pre_wc_afc_input_current = <500>;
		battery,prepare_ta_delay = <0>; /* msec */

		battery,swelling_high_temp_block = <410>;
		battery,swelling_high_temp_recov = <390>;
		battery,swelling_low_temp_block_1st = <150>;
		battery,swelling_low_temp_recov_1st = <170>;
		battery,swelling_low_temp_block_2nd = <50>;
		battery,swelling_low_temp_recov_2nd = <70>;

		battery,swelling_drop_float_voltage = <4150>;
		battery,swelling_high_rechg_voltage = <4000>;
		battery,swelling_low_rechg_voltage = <4000>;

		battery,siop_input_limit_current = <1200>;
		battery,siop_charging_limit_current = <1000>;
		battery,siop_hv_input_limit_current = <700>;
		battery,siop_hv_input_limit_current_2nd = <550>;
		battery,siop_hv_charging_limit_current = <1000>;

		battery,rp_current_rp1 = <500>;
		battery,rp_current_rp2 = <1500>;
		battery,rp_current_rp3 = <3000>;
		battery,rp_current_rdu_rp3 = <2100>;
		battery,rp_current_abnormal_rp3 = <1800>;

		battery,pd_charging_charge_power = <15000>;
		battery,max_charging_current = <2350>;

		battery,store_mode_charging_max = <70>;
		battery,store_mode_charging_min = <60>;

		battery,wireless_cc_cv = <85>;
		battery,wireless_otg_input_current = <900>;

		/* cycle, chg_float_voltage, recharge_condition_vcell, full_condition_vcell, full_condition_soc, step charging condition */
		battery,age_data = <0 4350 4280 4250 93
			300 4330 4260 4230 92
			400 4310 4240 4210 91
			700 4290 4220 4190 90
			1000 4240 4170 4140 89>;

		battery,max_input_voltage = <9000>; /* mV */
		battery,max_input_current = <3000>;  /* mA */

		battery,cisd_alg_index = <8>;
		battery,cisd_max_voltage_thr = <4400>; /* batttery ovp dettection voltage */
		battery,ignore_cisd_index = <0 0>;
		battery,ignore_cisd_index_d = <0 80>; /* Do not use BUCK_OFF_PER_DAY, DROP_SENSOR_PER_DAY */

		battery,expired_time = <10800>;
		battery,recharging_expired_time = <5400>;

		battery,battery_full_capacity = <3300>;

		io-channels = <&auxadc 3>;
		io-channel-names = "adc-chg-temp", "n/a", "n/a", "n/a", "n/a";
	};

	/* sec_battery_cable
	 *   0	UNKNOWN,
	 *   1	NONE,
	 *   2	PREPARE_TA,
	 *   3	TA,
	 *   4	USB,
	 *   5	USB_CDP,
	 *   6	9V_TA,
	 *   7	9V_ERR,
	 *   8	9V_UNKNOWN,
	 *   9	12V_TA,
	 *  10	WIRELESS,
	 *  11	HV_WIRELESS,
	 *  12	PMA_WIRELESS,
	 *  13	WIRELESS_PACK,
	 *  14	CABLE_WIRELESS_HV_PACK,
	 *  15	WIRELESS_STAND,
	 *  16	WIRELESS_HV_STAND,
	 *  17	QC20,
	 *  18	QC30,
	 *  19	PDIC,
	 *  20	UARTOFF,
	 *  21	OTG,
	 *  22	LAN_HUB,
	 *  23	POWER_SHARING,
	 *  24	HMT_CONNECTED,
	 *  25	HMT_CHARGE,
	 *  26	HV_TA_CHG_LIMIT,
	 *  27	WIRELESS_VEHICLE,
	 *  28	WIRELESS_HV_VEHICLE,
	 *  29	PREPARE_WIRELESS_HV,
	 *  30  TIMEOUT,
	 *  31  SMART_OTG,
	 *  32  SMART_NOTG,
	 *  33  WIRELESS_TX,
	 *  34	HV_WIRELESS_20,
	 *  35	HV_WIRELESS_20_LIMIT,
	 *  36	WIRELESS_FAKE,
	 *  37  PREPARE_WIRELESS_20,
	 *  38	CABLE_PDIC_APDO,
	 *  39	CABLE_MAX,
	 */
	sec_battery_cable: cable-info {
		default_input_current = <1800>;
		default_charging_current = <2100>;
		full_check_current_1st = <350>;
		full_check_current_2nd = <200>;

		current_group_1 {
			cable_number = <
				SEC_BATTERY_CABLE_PREPARE_TA
				SEC_BATTERY_CABLE_PDIC
				SEC_BATTERY_CABLE_OTG
				SEC_BATTERY_CABLE_LAN_HUB
				SEC_BATTERY_CABLE_POWER_SHARING>;
			input_current = <500>;
			charging_current = <500>;
		};
		current_group_2 {
			cable_number = <
				SEC_BATTERY_CABLE_HMT_CHARGE
				SEC_BATTERY_CABLE_SMART_OTG>;
			input_current = <1000>;
			charging_current = <1000>;
		};
		current_group_3 {
			cable_number = <
				SEC_BATTERY_CABLE_USB_CDP
				SEC_BATTERY_CABLE_SMART_NOTG>;
			input_current = <1500>;
			charging_current = <1500>;
		};
		current_group_4 {
			cable_number = <SEC_BATTERY_CABLE_9V_TA SEC_BATTERY_CABLE_9V_ERR
				SEC_BATTERY_CABLE_9V_UNKNOWN SEC_BATTERY_CABLE_QC20
				SEC_BATTERY_CABLE_QC30 SEC_BATTERY_CABLE_9V_POGO>;
			input_current = <1650>;
			charging_current = <2350>;
		};
		current_group_5 {
			cable_number = <SEC_BATTERY_CABLE_12V_TA>;
			input_current = <1650>;
			charging_current = <2350>;
		};
		current_group_6 {
			cable_number = <
				SEC_BATTERY_CABLE_WIRELESS
				SEC_BATTERY_CABLE_PMA_WIRELESS
				SEC_BATTERY_CABLE_WIRELESS_STAND
				SEC_BATTERY_CABLE_WIRELESS_VEHICLE
				SEC_BATTERY_CABLE_WIRELESS_TX
				SEC_BATTERY_CABLE_WIRELESS_FAKE>;
			input_current = <800>;
			charging_current = <2350>;
		};
		current_group_7 {
			cable_number = <SEC_BATTERY_CABLE_WIRELESS_PACK>;
			input_current = <700>;
			charging_current = <2350>;
		};
		current_group_8 {
			cable_number = <SEC_BATTERY_CABLE_HMT_CONNECTED>;
			input_current = <1000>;
			charging_current = <450>;
		};
		current_group_9 {
			cable_number = <SEC_BATTERY_CABLE_HV_TA_CHG_LIMIT>;
			input_current = <1800>;
			charging_current = <1800>;
		};
		current_group_10 {
			cable_number = <
				SEC_BATTERY_CABLE_HV_WIRELESS
				SEC_BATTERY_CABLE_WIRELESS_HV_PACK
				SEC_BATTERY_CABLE_WIRELESS_HV_STAND
				SEC_BATTERY_CABLE_WIRELESS_HV_VEHICLE
				SEC_BATTERY_CABLE_HV_WIRELESS_20_LIMIT>;
			input_current = <650>;
			charging_current = <2350>;
		};
		current_group_11 {
			cable_number = <
				SEC_BATTERY_CABLE_PREPARE_WIRELESS_HV
				SEC_BATTERY_CABLE_PREPARE_WIRELESS_20>;
			input_current = <500>;
			charging_current = <1200>;
		};
		current_group_12 {
			cable_number = <
				SEC_BATTERY_CABLE_NONE
				SEC_BATTERY_CABLE_USB
				SEC_BATTERY_CABLE_TIMEOUT>;
			input_current = <475>;
			charging_current = <550>;
		};
		current_group_13 {
			cable_number = <SEC_BATTERY_CABLE_HV_WIRELESS_20>;
			input_current = <1200>;
			charging_current = <2350>;
		};
	};
};

/* /home/dpi/qb5_8814/workspace/P4_1716/android/kernel/kmodule/battery/common/dts/battery_common.a13x.dtsi */
&sec_battery {
		pinctrl-names = "default";

		battery,chip_vendor = "MTK";

		battery,temp_check_type = <SEC_BATTERY_TEMP_CHECK_ADC>;
		battery,chg_temp_check_type = <SEC_BATTERY_TEMP_CHECK_ADC>;

		battery,thermal_source = <SEC_BATTERY_THERMAL_SOURCE_FG_ADC>;
		battery,chg_thermal_source = <SEC_BATTERY_THERMAL_SOURCE_ADC>;

		battery,temp_table_adc = <
					205 254 281 324 385 458 539 589 680 793
					938 1073 1220 1348 1506 1671 1831 1982 2131 2259
					2372 2468 2545
					>;
		battery,temp_table_data = <
					900 850 800 750 700 650 600 550 500 450
					400 350 300 250 200 150 100 50 0 (-50)
					(-100) (-150) (-200)
					>;

		battery,chg_temp_table_adc = <
					361 421 463 541 642 758 911 1000 1151 1345
					1597 1853 2096 2263 2606 2911 3195 3466 3721 3950
					4126 4126 4126
					>;
		battery,chg_temp_table_data = <
					900 850 800 750 700 650 600 550 500 450
					400 350 300 250 200 150 100 50 0 (-50)
					(-100) (-150) (-200)
					>;

		battery,temp_check_count = <1>;
		battery,overheatlimit_threshold = <700>;
		battery,overheatlimit_recovery = <680>;

		battery,wire_warm_overheat_thresh = <500>;
		battery,wire_normal_warm_thresh = <420>;
		battery,wire_cool1_normal_thresh = <180>;
		battery,wire_cool2_cool1_thresh = <150>;
		battery,wire_cool3_cool2_thresh = <50>;
		battery,wire_cold_cool3_thresh = <0>;

		battery,wire_warm_current = <1750>;	/* 0.36C */
		battery,wire_cool1_current = <2500>; /* 0.72C */
		battery,wire_cool2_current = <1150>;	/* 0.24C */
		battery,wire_cool3_current = <490>;	/* 0.1C */

		battery,high_temp_topoff = <250>;
		battery,low_temp_topoff = <250>;
		battery,high_temp_float = <4150>;
		battery,low_temp_float = <4350>;

		battery,chg_high_temp = <550>;
		battery,chg_high_temp_recovery = <520>;
		battery,chg_input_limit_current = <1000>;
		battery,chg_charging_limit_current = <1900>;

		battery,full_check_type = <SEC_BATTERY_FULLCHARGED_FG_CURRENT>;
		battery,full_check_type_2nd = <SEC_BATTERY_FULLCHARGED_FG_CURRENT>;

		battery,full_condition_vcell = <4250>;
		battery,recharge_condition_vcell = <4280>;
		battery,chg_float_voltage = <4350>;

		battery,swelling_high_rechg_voltage = <4000>;
		battery,swelling_low_rechg_voltage = <4200>;

		battery,max_charging_current = <2500>;
		battery,max_charging_charge_power = <15000>; /* 15W */

		/* cycle, chg_float_voltage, recharge_condition_vcell, full_condition_vcell, full_condition_soc, step charging condition */
		battery,age_data = <0 4350 4280 4250 93
			300 4330 4260 4230 92
			400 4310 4240 4210 91
			700 4290 4220 4190 90
			1000 4240 4170 4140 89>;

		battery,health_condition = <
			/* CYCLE ASOC */
			900 0  /* GOOD */
			1200 0 /* NORMAL */
			1500 0 /* AGED */
			>;

		battery,siop_scenarios = <20>;
		battery,siop_curr_type_num = <3>;
		/* nv, hv, fpdo */
		battery,siop_icl_20 = <1000 1000 1000>; /* 5W SIOP_DEFAULT 5W */
		battery,siop_fcc_20 = <SIOP_DEFAULT SIOP_DEFAULT SIOP_DEFAULT>;

		battery,standard_curr = <2500>;
		battery,expired_time = <12000>; /* 140 + 60 minutes */
		battery,recharging_expired_time = <5400>;
		battery,battery_full_capacity = <5000>;
		battery,cisd_max_voltage_thr = <5000>; /* batttery ovp dettection voltage */

		battery,volt_from_pmic;
		battery,pd_comm_cap;

		battery,ttf_hv_charge_current = <2480>;
		battery,ttf_capacity = <4350>;
		battery,cv_data = <
					2575	820	2968
					2559	850	2728
					2376	880	2488
					2053	910	2209
					1690	940	1870
					834	970	859
					561	990	263
					473	1000	0
					>;
};

&sec_battery_cable {
		full_check_current_1st = <500>;
		full_check_current_2nd = <250>;

		current_group_4 {
			charging_current = <2500>;
		};
		current_group_5 {
			charging_current = <2500>;
		};
		current_group_6 {
			charging_current = <2500>;
		};
		current_group_7 {
			charging_current = <2500>;
		};
		current_group_10 {
			charging_current = <2500>;
		};
};

/* /home/dpi/qb5_8814/workspace/P4_1716/android/kernel/kmodule/battery/common/dts/battery_common.a13x_eur_open.dtsi */
&sec_battery {
		battery,temp_table_adc = <
					205 275 304 314 369 428 512 591 685 794
					924 1065 1215 1378 1542 1687 1854 2011 2154 2284
					2422 2506 2570
					>;
		battery,temp_table_data = <
					900 850 800 750 700 650 600 550 500 450
					400 350 300 250 200 150 100 50 0 (-50)
					(-100) (-150) (-200)
					>;

		battery,slowcharging_usb_bootcomplete;
		battery,dynamic_cv_factor;
};

/* #include "../dc_vibrator.dtsi" */                 /* From dc_vibrator.py */
/ {
	fragment@smd {
		target-path = "/";
			__overlay__ {
				samsung_mobile_device {
					dc_vibrator {
						compatible = "samsung,dc_vibrator";
						status = "okay";
						dc_vib,motor_type = "COINDC";
#if 1
						dc_vib,regulator_name = "dc_vib";
						dc_vib-supply = <&mt_pmic_vibr_ldo_reg>;
#endif
					};
				};
			};
	};
};

/* #include "../fingerprint_et5xx.dtsi" */           /* From fingerprint_et5xx.py */
/*
 * Copyright (c) 2012-2013, The Linux Foundation. All rights reserved.
 *
 * This program is free software; you can redistribute it and/or modify
 * it under the terms of the GNU General Public License version 2 and
 * only version 2 as published by the Free Software Foundation.
 *
 * This program is distributed in the hope that it will be useful,
 * but WITHOUT ANY WARRANTY; without even the implied warranty of
 * MERCHANTABILITY or FITNESS FOR A PARTICULAR PURPOSE.  See the
 * GNU General Public License for more details.
 */

/* drive-strength */
&pio {
	btp_irq: btp-irq {
		pins_cmd_dat{
			pinmux = <MTK_PINMUX(SEC_GPIO_NUM(AP,pio,15), 0)>;
			bias-disable;
			drive-strength = <1>;
		};
	};
	btp_irq_sleep: btp-irq-sleep {
		pins_cmd_dat{
			pinmux = <MTK_PINMUX(SEC_GPIO_NUM(AP,pio,15), 0)>;
			bias-pull-down;
			input-enable;
			drive-strength = <1>;
		};
	};
};
#if 0
&${fps_ldo_vdd_3p3_parent} {
	btp_ldo_en: btp_ldo_enable {
		pins_cmd_dat{
			pinmux = <MTK_PINMUX(SEC_GPIO_NUM(${fps_ldo_vdd_3p3}), 0)>;
			bias-pull-down;
			drive-strength = <1>;
		};
	};
};
#endif

&pio {
	btp_sleep: btp_sleep_enable {
		pins_cmd_dat{
			pinmux = <MTK_PINMUX(SEC_GPIO_NUM(AP,pio,48), 0)>;
			bias-pull-down;
			drive-strength = <1>;
		};
	};
};

&pio {
	spi5_set_miso: set_miso {
		pins_cmd_dat{
			pinmux = <MTK_PINMUX(SEC_GPIO_NUM(AP,pio,38), 1)>;
			drive-strength = <4>;
		};
	};
	spi5_set_cs: set_cs {
		pins_cmd_dat{
			pinmux = <MTK_PINMUX(SEC_GPIO_NUM(AP,pio,36), 1)>;
			drive-strength = <4>;
		};
	};
	spi5_set_mosi: set_mosi {
		pins_cmd_dat{
			pinmux = <MTK_PINMUX(SEC_GPIO_NUM(AP,pio,37), 1)>;
			drive-strength = <4>;
		};
	};
	spi5_set_clk: set_clk {
		pins_cmd_dat{
			pinmux = <MTK_PINMUX(SEC_GPIO_NUM(AP,pio,35), 1)>;
			drive-strength = <4>;
		};
	};
	spi5_clr_miso: clr_miso {
		pins_cmd_dat{
			pinmux = <MTK_PINMUX(SEC_GPIO_NUM(AP,pio,38), 0)>;
			slew-rate = <0>;
			bias-pull-down;
			input-enable;
			drive-strength = <1>;
		};
	};
	spi5_clr_cs: clr_cs {
		pins_cmd_dat{
			pinmux = <MTK_PINMUX(SEC_GPIO_NUM(AP,pio,36), 0)>;
			slew-rate = <0>;
			bias-pull-down;
			output-low;
			drive-strength = <1>;
		};
	};
	spi5_clr_mosi: clr_mosi {
		pins_cmd_dat{
			pinmux = <MTK_PINMUX(SEC_GPIO_NUM(AP,pio,37), 0)>;
			slew-rate = <0>;
			bias-pull-down;
			output-low;
			drive-strength = <1>;
		};
	};
	spi5_clr_clk: clr_clk {
		pins_cmd_dat{
			pinmux = <MTK_PINMUX(SEC_GPIO_NUM(AP,pio,35), 0)>;
			slew-rate = <0>;
			bias-pull-down;
			output-low;
			drive-strength = <1>;
		};
	};
};
#if 1
&mt_pmic_vio28_ldo_reg {
    regulator-name = "VDD_BTP_3P3";
    regulator-min-microvolt = <3300000>;
    regulator-max-microvolt = <3300000>;
};
#endif
#if defined(CONFIG_SEC_FACTORY) || !1
&spi5 {
	status = "okay";
#else
&smd {
#endif
	#address-cells = <1>;
	#size-cells = <0>;

	etspi-spi@0 {
		compatible = "etspi,et5xx";
		reg = <0x00>;
		spi-max-frequency = <25000000>;
#if !defined(CONFIG_SEC_FACTORY) && 1
		clocks = <&topckgen_clk CLK_TOP_MAINPLL_D5_D4>,
			<&topckgen_clk CLK_TOP_SPI_SEL>,
			<&infracfg_ao_clk CLK_IFRAO_SPI5>;
		clock-names = "parent-clk", "sel-clk", "spi-clk";
#endif
		pinctrl-names = "default", "pins_poweron", "pins_poweroff", "pins_poweron_tz", "pins_poweroff_tz";
#if 0
		pinctrl-0 = <&btp_sleep &btp_irq &btp_ldo_en>;
#else
		pinctrl-0 = <&btp_sleep &btp_irq>;
#endif
		pinctrl-1 = <&spi5_set_miso &spi5_set_cs &spi5_set_mosi &spi5_set_clk>;
		pinctrl-2 = <&btp_sleep &spi5_clr_miso &spi5_clr_cs &spi5_clr_mosi &spi5_clr_clk>;
		pinctrl-3 = <&btp_irq>;
		pinctrl-4 = <&btp_irq_sleep>;
		gpio-controller;
		#gpio-cells = <2>;
#if 0
		etspi-ldoPin = <SEC_GPIO_REF(${fps_ldo_vdd_3p3}) 0>;
#endif
#if 1
		etspi-regulator = "VDD_BTP_3P3";
#endif
		etspi-sleepPin = <SEC_GPIO_REF(AP,pio,48) 0>;
		etspi-drdyPin = <SEC_GPIO_REF(AP,pio,15) 0>;
		etspi-chipid = "ET528";
		etspi-orient = <2>;
		controller-data {
			mediatek,tckdly = <1>;	/* It'll be used after tckdly patch */
		};
	};
};

/* #include "../nfc_nxp.dtsi" */                     /* From nfc_nxp.py */
/*
 * This program is free software; you can redistribute it and/or modify
 * it under the terms of the GNU General Public License version 2 and
 * only version 2 as published by the Free Software Foundation.
 *
 * This program is distributed in the hope that it will be useful,
 * but WITHOUT ANY WARRANTY; without even the implied warranty of
 * MERCHANTABILITY or FITNESS FOR A PARTICULAR PURPOSE.  See the
 * GNU General Public License for more details.
 */

&pio {
	nfc_ven: nfc_ven {
		pins_cmd_dat{
			pinmux = <MTK_PINMUX(SEC_GPIO_NUM(AP,pio,136), 0)>;
			output-low;
			bias-disable;
		};
	};
	ven_nc: ven_nc {
		pins_cmd_dat{
			pinmux = <MTK_PINMUX(SEC_GPIO_NUM(AP,pio,136), 0)>;
			input-enable;
			bias-pull-down;
		};
	};
};

&pio {
	nfc_firm: nfc_firm {
		pins_cmd_dat{
			pinmux = <MTK_PINMUX(SEC_GPIO_NUM(AP,pio,137), 0)>;
			output-low;
			bias-disable;
		};
	};
	firm_nc: firm_nc {
		pins_cmd_dat{
			pinmux = <MTK_PINMUX(SEC_GPIO_NUM(AP,pio,137), 0)>;
			input-enable;
			bias-pull-down;
		};
	};
};

&pio {
	nfc_clk_req: nfc_clk_req {
		pins_cmd_dat{
			pinmux =  <MTK_PINMUX(SEC_GPIO_NUM(AP,pio,13), 0)>;
			input-enable;
			bias-pull-down;
		};
	};
	clk_req_nc: clk_req_nc {
		pins_cmd_dat{
			pinmux =  <MTK_PINMUX(SEC_GPIO_NUM(AP,pio,13), 0)>;
			input-enable;
			bias-pull-down;
		};
	};
};

&pio {
	nfc_irq: nfc_irq {
		pins_cmd_dat {
			pinmux = <MTK_PINMUX(SEC_GPIO_NUM(AP,pio,5), 0)>;
			input-enable;
			bias-pull-down;
		};
	};

	irq_nc: irq_nc {
		pins_cmd_dat {
			pinmux = <MTK_PINMUX(SEC_GPIO_NUM(AP,pio,5), 0)>;
			input-enable;
			bias-pull-down;
		};
	};
};

&pio {
	nfc_i2c_off: nfc_i2c_off {
		pins_cmd_dat {
			pinmux = <MTK_PINMUX(SEC_GPIO_NUM(AP,pio,103), 0)>,
					<MTK_PINMUX(SEC_GPIO_NUM(AP,pio,104), 0)>;
			input-enable;
			bias-pull-down;
		};
	};
	nfc_i2c_on: nfc_i2c_on {
		pins_cmd_dat {
			pinmux = <MTK_PINMUX(SEC_GPIO_NUM(AP,pio,103), 1)>,
					<MTK_PINMUX(SEC_GPIO_NUM(AP,pio,104), 1)>;
			bias-pull-up;
		};
	};
};

#if 1
&pio {
	nfc_check: nfc_check {
		pins_cmd_dat {
			pinmux = <MTK_PINMUX(SEC_GPIO_NUM(AP,pio,181), 0)>;
			input-enable;
			bias-disable;
		};
	};
};
#endif

&i2c3 {
	status = "ok";
	clock-frequency = <400000>;
	mediatek,use-open-drain;

	pn547@2B {
		compatible = "pn547";
		reg = <0x2B>;

		interrupt-parent = <&pio>;
		interrupts = <SEC_GPIO_NUM(AP,pio,5) IRQ_TYPE_EDGE_RISING
			SEC_GPIO_NUM(AP,pio,5) 0>;

		pn547,irq-gpio = <SEC_GPIO_REF(AP,pio,5) 0>;
		pn547,ven-gpio = <SEC_GPIO_REF(AP,pio,136) 0>;
		pn547,firm-gpio = <SEC_GPIO_REF(AP,pio,137) 0>;
		pn547,clk_req-gpio = <SEC_GPIO_REF(AP,pio,13) 0>;
#if 1
		pn547,clk_req_wake;
#endif
#if 1
		nfc_pvdd-supply = <&mt_pmic_vfp_ldo_reg>;
#endif
		pn547,ldo_control;
#if 1
		pn547,nfc-det-gpio = <SEC_GPIO_REF(AP,pio,181) 0>;
#endif
		pn547,ap_vendor = "mtk";
		pinctrl-names = "default", "nfc_nc", "i2c_off";
		pinctrl-0 = <&nfc_ven &nfc_firm &nfc_clk_req &nfc_irq &nfc_i2c_on
#if 1
					&nfc_check
#endif
					>;
		pinctrl-1 = <&ven_nc &firm_nc &clk_req_nc &irq_nc &nfc_i2c_off>;
		pinctrl-2 = <&nfc_i2c_off>;
	};
};

#if 0
#if 0 && !defined(CONFIG_SEC_FACTORY)
&tlmm {
/*	gpio-reserved-ranges = <SEC_GPIO_NUM(${ese_spi_miso}) 4>; */
};
#endif

&${ese_spi_parent} {
	ese_spi_bus_func: spi_bus_func {
		pins_cmd_dat {
			/* spi func is 2, but this can be different by AP */
			pinmux = <MTK_PINMUX(SEC_GPIO_NUM(${ese_spi_miso}), 2)>,
				<MTK_PINMUX(SEC_GPIO_NUM(${ese_spi_mosi}), 2)>,
				<MTK_PINMUX(SEC_GPIO_NUM(${ese_spi_cs}), 2)>,
				<MTK_PINMUX(SEC_GPIO_NUM(${ese_spi_clk}), 2)>;
			bias-disable;
		};
	};

	ese_spi_cs_sleep: spi_cs_sleep {
		pins_cmd_dat {
			pinmux = <MTK_PINMUX(SEC_GPIO_NUM(${ese_spi_cs}), 0)>;
			output-high;
			bias-pull-up;
		};
	};

	ese_spi_clk_sleep: spi_clk_sleep {
		pins_cmd_dat {
			pinmux = <MTK_PINMUX(SEC_GPIO_NUM(${ese_spi_clk}), 0)>;
			output-low;
			bias-pull-down;
		};
	};

	ese_spi_mosi_sleep: spi_mosi_sleep {
		pins_cmd_dat {
			pinmux = <MTK_PINMUX(SEC_GPIO_NUM(${ese_spi_mosi}), 0)>;
			output-low;
			bias-pull-down;
		};
	};

	ese_spi_miso_sleep: spi_miso_sleep {
		pins_cmd_dat {
			pinmux = <MTK_PINMUX(SEC_GPIO_NUM(${ese_spi_miso}), 0)>;
			input-enable;
			bias-disable;
		};
	};

	ese_spi_all_out_low: spi_all_out_low {
		pins_cmd_dat {
			pinmux = <MTK_PINMUX(SEC_GPIO_NUM(${ese_spi_miso}), 0)>,
				<MTK_PINMUX(SEC_GPIO_NUM(${ese_spi_mosi}), 0)>,
				<MTK_PINMUX(SEC_GPIO_NUM(${ese_spi_cs}), 0)>,
				<MTK_PINMUX(SEC_GPIO_NUM(${ese_spi_clk}), 0)>;
			output-low;
			bias-pull-down;
		};
	};
};

#if 0
&${ese_check_parent} {
	ese_check_default: check_default {
		pins_cmd_dat {
			pinmux = <MTK_PINMUX(SEC_GPIO_NUM(${ese_check}), 0)>;
			input-enable;
			bias-disable;
		};
	};
};
#endif

/* #active
 * - function/no-pull/X
 * #idle
 * - mosi,clk: out/pull-down/low
 * - cs: out/pull-up/high
 * - miso: input/pull-non/X
 */
&${ese_spi} {
	status = "ok";
	/delete-property/ pinctrl-names;
	/delete-property/ pinctrl-0;
	pinctrl-names = "ese_on", "ese_off", "lpm";
	pinctrl-0 = <&ese_spi_bus_func>;
	pinctrl-1 = <&ese_spi_cs_sleep &ese_spi_clk_sleep &ese_spi_mosi_sleep &ese_spi_miso_sleep>;
	pinctrl-2 = <&ese_spi_all_out_low>;

	ese_spi@0 {
		compatible = "p61";
		reg = <0>;
		spi-max-frequency = <8000000>;
		p61,ap_vendor = "mtk";
#if 0
		ese-det-gpio = <SEC_GPIO_REF(${ese_check}) 0>;
		pinctrl-names = "default";
		pinctrl-0 = <&ese_check_default>;
#endif
	};
};
#endif

/* revision devicetree for general */
#include "mt6833.a13x_eur_open.12.dtsi"

/ {
	compatible = "Mediatek,MT6833","Samsung,A13x EUR OPEN 12";
	dtbo-hw_rev = <12>;
	dtbo-hw_rev_end = <32>;
};
